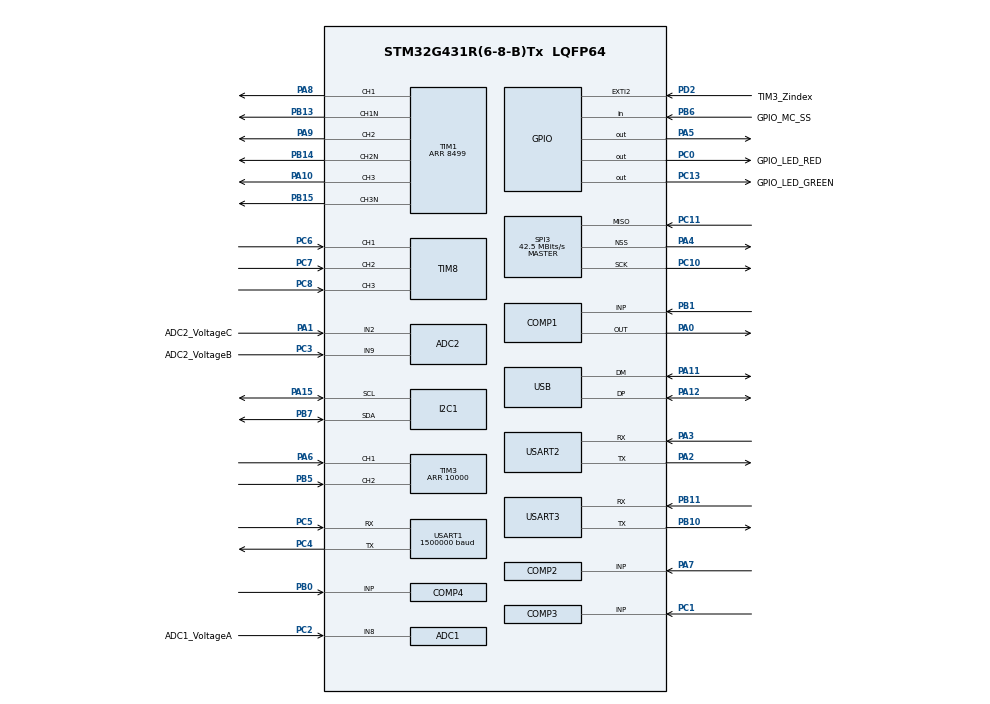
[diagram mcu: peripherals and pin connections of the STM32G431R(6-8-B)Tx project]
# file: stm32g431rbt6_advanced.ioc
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ADC1.Channel-0\#ChannelRegularConversion=ADC_CHANNEL_12
ADC1.Channel-2\#ChannelRegularConversion=ADC_CHANNEL_VREFINT
ADC1.DataAlign=ADC_DATAALIGN_LEFT
ADC1.EnableInjectedConversion=ENABLE
ADC1.ExternalTrigInjecConv=ADC_EXTERNALTRIGINJEC_T1_TRGO
ADC1.InjNumberOfConversion=3
ADC1.InjectedChannel-1\#ChannelInjectedConversion=ADC_CHANNEL_7
ADC1.InjectedChannel-3\#ChannelInjectedConversion=ADC_CHANNEL_8
ADC1.InjectedChannel-4\#ChannelInjectedConversion=ADC_CHANNEL_15
ADC1.InjectedOffsetNumber-1\#ChannelInjectedConversion=ADC_OFFSET_NONE
ADC1.InjectedOffsetNumber-3\#ChannelInjectedConversion=ADC_OFFSET_NONE
ADC1.InjectedOffsetNumber-4\#ChannelInjectedConversion=ADC_OFFSET_NONE
ADC1.InjectedRank-1\#ChannelInjectedConversion=1
ADC1.InjectedRank-3\#ChannelInjectedConversion=2
ADC1.InjectedRank-4\#ChannelInjectedConversion=3
ADC1.InjectedSamplingTime-1\#ChannelInjectedConversion=ADC_SAMPLETIME_2CYCLES_5
ADC1.InjectedSamplingTime-3\#ChannelInjectedConversion=ADC_SAMPLETIME_2CYCLES_5
ADC1.InjectedSamplingTime-4\#ChannelInjectedConversion=ADC_SAMPLETIME_2CYCLES_5
ADC1.NbrOfConversion=2
ADC1.NbrOfConversionFlag=1
ADC1.OffsetNumber-0\#ChannelRegularConversion=ADC_OFFSET_NONE
ADC1.OffsetNumber-2\#ChannelRegularConversion=ADC_OFFSET_NONE
ADC1.Rank-0\#ChannelRegularConversion=1
ADC1.Rank-2\#ChannelRegularConversion=2
ADC1.Rank2_Channel=ADC_CHANNEL_8
ADC1.Rank3_Channel=ADC_CHANNEL_15
ADC1.SamplingTime-0\#ChannelRegularConversion=ADC_SAMPLETIME_6CYCLES_5
ADC1.SamplingTime-2\#ChannelRegularConversion=ADC_SAMPLETIME_2CYCLES_5
ADC1.master=1
ADC2.DataAlign=ADC_DATAALIGN_LEFT
ADC2.EnableInjectedConversion=ENABLE
ADC2.EnableRegularConversion=DISABLE
ADC2.ExternalTrigInjecConv=ADC_EXTERNALTRIGINJEC_T1_TRGO
ADC2.InjNumberOfConversion=3
ADC2.InjectedChannel-1\#ChannelInjectedConversion=ADC_CHANNEL_4
ADC2.InjectedChannel-2\#ChannelInjectedConversion=ADC_CHANNEL_9
ADC2.InjectedChannel-3\#ChannelInjectedConversion=ADC_CHANNEL_2
ADC2.InjectedOffsetNumber-1\#ChannelInjectedConversion=ADC_OFFSET_NONE
ADC2.InjectedOffsetNumber-2\#ChannelInjectedConversion=ADC_OFFSET_NONE
ADC2.InjectedOffsetNumber-3\#ChannelInjectedConversion=ADC_OFFSET_NONE
ADC2.InjectedRank-1\#ChannelInjectedConversion=1
ADC2.InjectedRank-2\#ChannelInjectedConversion=2
ADC2.InjectedRank-3\#ChannelInjectedConversion=3
ADC2.InjectedSamplingTime-1\#ChannelInjectedConversion=ADC_SAMPLETIME_2CYCLES_5
ADC2.InjectedSamplingTime-2\#ChannelInjectedConversion=ADC_SAMPLETIME_2CYCLES_5
ADC2.InjectedSamplingTime-3\#ChannelInjectedConversion=ADC_SAMPLETIME_2CYCLES_5
ADC2.Rank1_Channel=ADC_CHANNEL_4
ADC2.Rank2_Channel=ADC_CHANNEL_9
ADC2.Rank3_Channel=ADC_CHANNEL_2
COMP1.Hysteresis=COMP_HYSTERESIS_70MV
COMP2.Hysteresis=COMP_HYSTERESIS_70MV
COMP3.Hysteresis=COMP_HYSTERESIS_70MV
COMP4.Hysteresis=COMP_HYSTERESIS_70MV
DAC3.DAC_Channel-DAC_OUT2_Int=DAC_CHANNEL_2
Dma.I2C1_RX.2.Direction=DMA_PERIPH_TO_MEMORY
Dma.I2C1_RX.2.EventEnable=DISABLE
Dma.I2C1_RX.2.Instance=DMA2_Channel2
Dma.I2C1_RX.2.MemDataAlignment=DMA_MDATAALIGN_BYTE
Dma.I2C1_RX.2.MemInc=DMA_MINC_ENABLE
Dma.I2C1_RX.2.Mode=DMA_CIRCULAR
Dma.I2C1_RX.2.PeriphDataAlignment=DMA_PDATAALIGN_BYTE
Dma.I2C1_RX.2.PeriphInc=DMA_PINC_DISABLE
Dma.I2C1_RX.2.Polarity=HAL_DMAMUX_REQ_GEN_RISING
Dma.I2C1_RX.2.Priority=DMA_PRIORITY_LOW
Dma.I2C1_RX.2.RequestNumber=1
Dma.I2C1_RX.2.SignalID=NONE
Dma.I2C1_RX.2.SyncEnable=DISABLE
Dma.I2C1_RX.2.SyncPolarity=HAL_DMAMUX_SYNC_NO_EVENT
Dma.I2C1_RX.2.SyncRequestNumber=1
Dma.I2C1_RX.2.SyncSignalID=NONE
Dma.Request0=USART1_RX
Dma.Request1=USART1_TX
Dma.Request2=I2C1_RX
Dma.Request3=SPI3_RX
Dma.SPI3_RX.3.Direction=DMA_PERIPH_TO_MEMORY
Dma.SPI3_RX.3.EventEnable=DISABLE
Dma.SPI3_RX.3.Instance=DMA2_Channel1
Dma.SPI3_RX.3.MemDataAlignment=DMA_MDATAALIGN_HALFWORD
Dma.SPI3_RX.3.MemInc=DMA_MINC_DISABLE
Dma.SPI3_RX.3.Mode=DMA_CIRCULAR
Dma.SPI3_RX.3.PeriphDataAlignment=DMA_PDATAALIGN_HALFWORD
Dma.SPI3_RX.3.PeriphInc=DMA_PINC_DISABLE
Dma.SPI3_RX.3.Polarity=HAL_DMAMUX_REQ_GEN_RISING
Dma.SPI3_RX.3.Priority=DMA_PRIORITY_LOW
Dma.SPI3_RX.3.RequestNumber=1
Dma.SPI3_RX.3.SignalID=NONE
Dma.SPI3_RX.3.SyncEnable=DISABLE
Dma.SPI3_RX.3.SyncPolarity=HAL_DMAMUX_SYNC_NO_EVENT
Dma.SPI3_RX.3.SyncRequestNumber=1
Dma.SPI3_RX.3.SyncSignalID=NONE
Dma.USART1_RX.0.Direction=DMA_PERIPH_TO_MEMORY
Dma.USART1_RX.0.EventEnable=DISABLE
Dma.USART1_RX.0.Instance=DMA1_Channel2
Dma.USART1_RX.0.MemDataAlignment=DMA_MDATAALIGN_BYTE
Dma.USART1_RX.0.MemInc=DMA_MINC_ENABLE
Dma.USART1_RX.0.Mode=DMA_CIRCULAR
Dma.USART1_RX.0.PeriphDataAlignment=DMA_PDATAALIGN_BYTE
Dma.USART1_RX.0.PeriphInc=DMA_PINC_DISABLE
Dma.USART1_RX.0.Polarity=HAL_DMAMUX_REQ_GEN_RISING
Dma.USART1_RX.0.Priority=DMA_PRIORITY_LOW
Dma.USART1_RX.0.RequestNumber=1
Dma.USART1_RX.0.SignalID=NONE
Dma.USART1_RX.0.SyncEnable=DISABLE
Dma.USART1_RX.0.SyncPolarity=HAL_DMAMUX_SYNC_NO_EVENT
Dma.USART1_RX.0.SyncRequestNumber=1
Dma.USART1_RX.0.SyncSignalID=NONE
Dma.USART1_TX.1.Direction=DMA_MEMORY_TO_PERIPH
Dma.USART1_TX.1.EventEnable=DISABLE
Dma.USART1_TX.1.Instance=DMA1_Channel1
Dma.USART1_TX.1.MemDataAlignment=DMA_MDATAALIGN_BYTE
Dma.USART1_TX.1.MemInc=DMA_MINC_ENABLE
Dma.USART1_TX.1.Mode=DMA_NORMAL
Dma.USART1_TX.1.PeriphDataAlignment=DMA_PDATAALIGN_BYTE
Dma.USART1_TX.1.PeriphInc=DMA_PINC_DISABLE
Dma.USART1_TX.1.Polarity=HAL_DMAMUX_REQ_GEN_RISING
Dma.USART1_TX.1.Priority=DMA_PRIORITY_LOW
Dma.USART1_TX.1.RequestNumber=1
Dma.USART1_TX.1.SignalID=NONE
Dma.USART1_TX.1.SyncEnable=DISABLE
Dma.USART1_TX.1.SyncPolarity=HAL_DMAMUX_SYNC_NO_EVENT
Dma.USART1_TX.1.SyncRequestNumber=1
Dma.USART1_TX.1.SyncSignalID=NONE
I2C1.Timing=0x30A0A7FB
Mcu.Family=STM32G4
Mcu.Name=STM32G431R(6-8-B)Tx
Mcu.Package=LQFP64
NVIC.ADC1_2_IRQn=true\:5\:0\:true\:false\:true\:true\:true\:true
NVIC.DMA1_Channel1_IRQn=true\:0\:0\:false\:false\:true\:false\:true\:true
NVIC.DMA1_Channel2_IRQn=true\:0\:0\:false\:false\:true\:false\:true\:true
NVIC.DMA2_Channel1_IRQn=true\:0\:0\:false\:false\:true\:false\:true\:true
NVIC.DMA2_Channel2_IRQn=true\:0\:0\:false\:false\:true\:false\:true\:true
NVIC.EXTI2_IRQn=true\:4\:0\:true\:false\:true\:true\:true\:true
NVIC.PriorityGroup=NVIC_PRIORITYGROUP_4
NVIC.USB_LP_IRQn=true\:0\:0\:false\:false\:true\:false\:true\:true
PA0.Mode=ExternalOutput
PA0.Signal=COMP1_OUT
PA1.GPIO_Label=ADC2_VoltageC
PA1.Mode=IN2-Single-Ended
PA1.Signal=ADC2_IN2
PA10.Signal=S_TIM1_CH3
PA11.Mode=Device
PA11.Signal=USB_DM
PA12.Mode=Device
PA12.Signal=USB_DP
PA13.Mode=Serial_Wire
PA13.Signal=SYS_JTMS-SWDIO
PA14.Mode=Serial_Wire
PA14.Signal=SYS_JTCK-SWCLK
PA15.GPIO_Pu=GPIO_PULLUP
PA15.Mode=I2C
PA15.Signal=I2C1_SCL
PA2.Mode=Asynchronous
PA2.Signal=USART2_TX
PA3.Mode=Asynchronous
PA3.Signal=USART2_RX
PA4.Mode=NSS_Signal_Hard_Output
PA4.Signal=SPI3_NSS
PA5.Signal=GPIO_Output
PA6.Signal=S_TIM3_CH1
PA7.Signal=SharedAnalog_PA7
PA8.Signal=S_TIM1_CH1
PA9.Signal=S_TIM1_CH2
PB0.Signal=SharedAnalog_PB0
PB1.Signal=SharedAnalog_PB1
PB10.Mode=Asynchronous
PB10.Signal=USART3_TX
PB11.Mode=Asynchronous
PB11.Signal=USART3_RX
PB13.Mode=PWM Generation1 CH1 CH1N
PB13.Signal=TIM1_CH1N
PB14.Mode=PWM Generation2 CH2 CH2N
PB14.Signal=TIM1_CH2N
PB15.Mode=PWM Generation3 CH3 CH3N
PB15.Signal=TIM1_CH3N
PB5.Signal=S_TIM3_CH2
PB6.GPIO_Label=GPIO_MC_SS
PB6.Signal=GPIO_Input
PB7.GPIO_Pu=GPIO_PULLUP
PB7.Mode=I2C
PB7.Signal=I2C1_SDA
PC0.GPIO_Label=GPIO_LED_RED
PC0.Signal=GPIO_Output
PC1.Signal=SharedAnalog_PC1
PC10.Mode=RX_Only_Simplex_Unidirect_Master
PC10.Signal=SPI3_SCK
PC11.Mode=RX_Only_Simplex_Unidirect_Master
PC11.Signal=SPI3_MISO
PC13.GPIO_Label=GPIO_LED_GREEN
PC13.Signal=GPIO_Output
PC14-OSC32_IN.Mode=LSE-External-Oscillator
PC14-OSC32_IN.Signal=RCC_OSC32_IN
PC15-OSC32_OUT.Mode=LSE-External-Oscillator
PC15-OSC32_OUT.Signal=RCC_OSC32_OUT
PC2.GPIO_Label=ADC1_VoltageA
PC2.Mode=IN8-Single-Ended
PC2.Signal=ADC1_IN8
PC3.GPIO_Label=ADC2_VoltageB
PC3.Mode=IN9-Single-Ended
PC3.Signal=ADC2_IN9
PC4.Mode=Asynchronous
PC4.Signal=USART1_TX
PC5.Mode=Asynchronous
PC5.Signal=USART1_RX
PC6.Signal=S_TIM8_CH1
PC7.Signal=S_TIM8_CH2
PC8.Signal=S_TIM8_CH3
PD2.GPIO_Label=TIM3_Zindex
PD2.GPIO_PuPd=GPIO_PULLDOWN
PD2.Signal=GPXTI2
PF0-OSC_IN.Mode=HSE-External-Oscillator
PF0-OSC_IN.Signal=RCC_OSC_IN
PF1-OSC_OUT.Mode=HSE-External-Oscillator
PF1-OSC_OUT.Signal=RCC_OSC_OUT
ProjectManager.HeapSize=0x200
ProjectManager.StackSize=0x400
ProjectManager.TargetToolchain=MDK-ARM V5.32
RCC.ADC12Freq_Value=170000000
RCC.AHBFreq_Value=170000000
RCC.APB1Freq_Value=170000000
RCC.APB1TimFreq_Value=170000000
RCC.APB2Freq_Value=170000000
RCC.APB2TimFreq_Value=170000000
RCC.CK48CLockSelection=RCC_USBCLKSOURCE_HSI48
RCC.CortexFreq_Value=170000000
RCC.EXTERNAL_CLOCK_VALUE=12288000
RCC.HCLKFreq_Value=170000000
RCC.HSE_VALUE=8000000
RCC.HSI48_VALUE=48000000
RCC.HSI_VALUE=16000000
RCC.PLLM=RCC_PLLM_DIV2
RCC.PLLN=85
RCC.PLLQ=RCC_PLLQ_DIV8
RCC.PLLSourceVirtual=RCC_PLLSOURCE_HSE
RCC.SYSCLKFreq_VALUE=170000000
RCC.SYSCLKSource=RCC_SYSCLKSOURCE_PLLCLK
RCC.USBFreq_Value=48000000
RCC.VCOOutputFreq_Value=340000000
SH.S_TIM1_CH1.0=TIM1_CH1,PWM Generation1 CH1 CH1N
SH.S_TIM1_CH2.0=TIM1_CH2,PWM Generation2 CH2 CH2N
SH.S_TIM1_CH3.0=TIM1_CH3,PWM Generation3 CH3 CH3N
SH.S_TIM3_CH1.0=TIM3_CH1,Encoder_Interface
SH.S_TIM3_CH2.0=TIM3_CH2,Encoder_Interface
SH.S_TIM8_CH1.0=TIM8_CH1,Xored_Inputs_Hall_Sensor_Interface
SH.S_TIM8_CH2.0=TIM8_CH2,Xored_Inputs_Hall_Sensor_Interface
SH.S_TIM8_CH3.0=TIM8_CH3,Xored_Inputs_Hall_Sensor_Interface
SH.SharedAnalog_PA7.0=COMP2_INP,INP
SH.SharedAnalog_PA7.1=ADC2_IN4,IN4-Single-Ended
SH.SharedAnalog_PB0.0=COMP4_INP,INP
SH.SharedAnalog_PB0.1=ADC1_IN15,IN15-Single-Ended
SH.SharedAnalog_PB1.0=COMP1_INP,INP
SH.SharedAnalog_PB1.1=ADC1_IN12,IN12-Single-Ended
SH.SharedAnalog_PC1.0=COMP3_INP,INP
SH.SharedAnalog_PC1.1=ADC1_IN7,IN7-Single-Ended
SPI3.BaudRatePrescaler=SPI_BAUDRATEPRESCALER_4
SPI3.CalculateBaudRate=42.5 MBits/s
SPI3.Direction=SPI_DIRECTION_2LINES_RXONLY
SPI3.Mode=SPI_MODE_MASTER
SPI3.VirtualNSS=VM_NSSHARD
SPI3.VirtualType=VM_MASTER
TIM1.Break2State=TIM_BREAK2_ENABLE
TIM1.BreakFilter=4
TIM1.BreakState=TIM_BREAK_ENABLE
TIM1.Channel-PWM\ Generation1\ CH1\ CH1N=TIM_CHANNEL_1
TIM1.Channel-PWM\ Generation2\ CH2\ CH2N=TIM_CHANNEL_2
TIM1.Channel-PWM\ Generation3\ CH3\ CH3N=TIM_CHANNEL_3
TIM1.CounterMode=TIM_COUNTERMODE_CENTERALIGNED1
TIM1.OCMode_PWM-PWM\ Generation1\ CH1\ CH1N=TIM_OCMODE_PWM2
TIM1.OCMode_PWM-PWM\ Generation2\ CH2\ CH2N=TIM_OCMODE_PWM2
TIM1.OCMode_PWM-PWM\ Generation3\ CH3\ CH3N=TIM_OCMODE_PWM2
TIM1.PeriodNoDither=8499
TIM1.RepetitionCounter=1
TIM1.SourceBRKCOMP2=TIM_BREAKINPUTSOURCE_ENABLE
TIM1.SourceBRKCOMP3=TIM_BREAKINPUTSOURCE_ENABLE
TIM1.SourceBRKCOMP4=TIM_BREAKINPUTSOURCE_ENABLE
TIM1.TIM_MasterOutputTrigger=TIM_TRGO_UPDATE
TIM3.EncoderMode=TIM_ENCODERMODE_TI12
TIM3.IC1Filter=3
TIM3.IC2Filter=3
TIM3.PeriodNoDither=10000
USART1.AutoBaudRateEnableParam=UART_ADVFEATURE_AUTOBAUDRATE_DISABLE
USART1.BaudRate=1500000
USART1.VirtualMode-Asynchronous=VM_ASYNC
USART2.VirtualMode-Asynchronous=VM_ASYNC
USART3.VirtualMode-Asynchronous=VM_ASYNC
USB.Sof_enable=DISABLE
USB_DEVICE.CLASS_NAME_FS=CDC
USB_DEVICE.VirtualMode=Cdc
USB_DEVICE.VirtualModeFS=Cdc_FS
VP_ADC1_Vref_Input.Mode=IN-Vrefint
VP_COMP1_VS_DAC1OUT1.Mode=INM_DAC1OUT1
VP_COMP2_VS_DAC3OUT2.Mode=INM_DAC3OUT2
VP_COMP3_VS_DAC3OUT1.Mode=INM_DAC3OUT1
VP_COMP4_VS_DAC3OUT2.Mode=INM_DAC3OUT2
VP_CORDIC_VS_CORDIC.Mode=CORDIC_Activate
VP_DAC1_VS_DACI1.Mode=DAC_OUT1_Int
VP_DAC3_VS_DACI1.Mode=DAC_OUT1_Int
VP_DAC3_VS_DACI2.Mode=DAC_OUT2_Int
VP_RNG_VS_RNG.Mode=RNG_Activate
VP_SYS_VS_DBSignals.Mode=DisableDeadBatterySignals
VP_SYS_V_VREFBUF.Mode=ExternalMode
VP_TIM16_VS_ClockSourceINT.Mode=Enable_Timer
VP_TIM1_VS_ClockSourceINT.Mode=Internal
VP_USB_DEVICE_VS_USB_DEVICE_CDC_FS.Mode=CDC_FS
board=custom

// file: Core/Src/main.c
/* USER CODE BEGIN Header */
/**
  ******************************************************************************
  * @file           : main.c
  * @brief          : Main program body
  ******************************************************************************
  * @attention
  *
  * Copyright (c) 2024 STMicroelectronics.
  * All rights reserved.
  *
  * This software is licensed under terms that can be found in the LICENSE file
  * in the root directory of this software component.
  * If no LICENSE file comes with this software, it is provided AS-IS.
  *
  ******************************************************************************
  */
/* USER CODE END Header */
#include "main.h"
#include "usb_device.h"

/* USER CODE BEGIN Includes */
#include "mcConfig.h"
#include "usbd_cdc_if.h"
/* USER CODE END Includes */

/* USER CODE BEGIN PM */
volatile uint16_t tempDat = 0u;
/* USER CODE END PM */

void SystemClock_Config(void);
static void MX_GPIO_Init(void);
static void MX_COMP1_Init(void);
static void MX_COMP2_Init(void);
static void MX_COMP3_Init(void);
static void MX_COMP4_Init(void);
static void MX_DAC1_Init(void);
static void MX_DAC3_Init(void);
static void MX_ADC1_Init(void);
static void MX_ADC2_Init(void);
static void MX_I2C1_Init(void);
static void MX_TIM1_Init(void);
static void MX_TIM8_Init(void);
static void MX_SPI3_Init(void);
static void MX_TIM3_Init(void);
static void MX_USART1_UART_Init(void);
static void MX_DMA_Init(void);
static void MX_USART3_UART_Init(void);
static void MX_USART2_UART_Init(void);
static void MX_CORDIC_Init(void);
static void MX_TIM16_Init(void);
static void MX_RNG_Init(void);

int main(void)
{

  /* MCU Configuration--------------------------------------------------------*/

  /* Reset of all peripherals, Initializes the Flash interface and the Systick. */
  HAL_Init();

  /* Configure the system clock */
  SystemClock_Config();

  /* Initialize all configured peripherals */
  MX_DMA_Init();
  MX_GPIO_Init();
  MX_COMP1_Init();
  MX_COMP2_Init();
  MX_COMP3_Init();
  MX_COMP4_Init();
  MX_DAC1_Init();
  MX_DAC3_Init();
  MX_ADC1_Init();
  MX_ADC2_Init();
  MX_I2C1_Init();
  MX_TIM1_Init();
  MX_TIM8_Init();
  MX_SPI3_Init();
  MX_TIM3_Init();
  MX_USART1_UART_Init();
  MX_USART3_UART_Init();
  MX_USART2_UART_Init();
  MX_CORDIC_Init();
  MX_TIM16_Init();
  MX_USB_Device_Init();
  MX_RNG_Init();
  /* USER CODE BEGIN 2 */
  /*=========================BOOT=================================*/
  uint32_t isBootFromMainFlash = READ_BIT(FLASH->SEC1R,FLASH_SEC1R_BOOT_LOCK);
  if(!isBootFromMainFlash){
    WRITE_REG(FLASH->KEYR,0x45670123);
    WRITE_REG(FLASH->KEYR,0xCDEF89AB);
    WRITE_REG(FLASH->OPTKEYR,0x08192A3B);
    WRITE_REG(FLASH->OPTKEYR,0x4C5D6E7F);
    while(READ_BIT(FLASH->SR,FLASH_SR_BSY));
    CLEAR_BIT(FLASH->CR,FLASH_CR_OPTLOCK);
    SET_BIT(FLASH->SEC1R,FLASH_SEC1R_BOOT_LOCK);
    SET_BIT(FLASH->CR,FLASH_CR_OPTSTRT);
    while(READ_BIT(FLASH->SR,FLASH_SR_BSY));
  }
  /*=========================Segger RTT=================================*/
  SEGGER_RTT_Init();

  /*===========================RNG===============================*/

  LL_RNG_Enable(RNG);

  /*===========================Cordic===============================*/

  LL_CORDIC_Config(CORDIC,LL_CORDIC_FUNCTION_SINE,LL_CORDIC_PRECISION_4CYCLES,LL_CORDIC_SCALE_0,LL_CORDIC_NBWRITE_1,LL_CORDIC_NBREAD_2,LL_CORDIC_INSIZE_32BITS,LL_CORDIC_OUTSIZE_32BITS);

  /*===========================CRC===============================*/

  /*===========================USB===============================*/

  USBD_Interface_fops_FS.Init();

  /*===========================OCP===============================*/

  LL_DAC_Enable(DAC3,LL_DAC_CHANNEL_1);
  LL_DAC_Enable(DAC3,LL_DAC_CHANNEL_2);

  LL_DAC_ConvertData12RightAligned(DAC3,LL_DAC_CHANNEL_1,4000);
  LL_DAC_ConvertData12RightAligned(DAC3,LL_DAC_CHANNEL_2,4000);

  LL_DAC_TrigSWConversion(DAC3,LL_DAC_CHANNEL_1);

  while(READ_BIT(DAC3->SWTRIGR,(LL_DAC_CHANNEL_1 & DAC_SWTR_CHX_MASK)));

  LL_DAC_TrigSWConversion(DAC3,LL_DAC_CHANNEL_2);

  while(READ_BIT(DAC3->SWTRIGR,(LL_DAC_CHANNEL_2 & DAC_SWTR_CHX_MASK)));

  LL_COMP_Enable(COMP2);
  LL_COMP_Enable(COMP3);
  LL_COMP_Enable(COMP4);
  /*===========================OVP===============================*/
  LL_DAC_Enable(DAC1,LL_DAC_CHANNEL_1);

  LL_DAC_ConvertData12RightAligned(DAC1,LL_DAC_CHANNEL_1,2500);

  LL_DAC_TrigSWConversion(DAC1,LL_DAC_CHANNEL_1);

  while(READ_BIT(DAC1->SWTRIGR,(LL_DAC_CHANNEL_1 & DAC_SWTR_CHX_MASK)));

  LL_COMP_Enable(COMP1);
  /*===========================SPI + DMA===============================*/
  // LL_SPI_EnableDMAReq_RX(SPI3);
  // LL_SPI_Enable(SPI3);

  // LL_DMA_ConfigAddresses(DMA2,LL_DMA_CHANNEL_1,(uint32_t)&SPI3->DR,(uint32_t)&pAbs->encoderOutput,LL_DMA_DIRECTION_PERIPH_TO_MEMORY);
  // LL_DMA_SetDataLength(DMA2,LL_DMA_CHANNEL_1,0xFFFF);
  // LL_DMA_EnableChannel(DMA2,LL_DMA_CHANNEL_1);
  /*===========================USART1 + TX +DMA===============================*/
  // LL_USART_EnableDMAReq_TX(USART1);
  // LL_DMA_ConfigAddresses(DMA1,LL_DMA_CHANNEL_1,(uint32_t)&frameSendForUSART,(uint32_t)&USART1->TDR,LL_DMA_DIRECTION_MEMORY_TO_PERIPH);
  // LL_DMA_SetDataLength(DMA1,LL_DMA_CHANNEL_1,sizeof(FrameSendForUSART));
  // LL_DMA_EnableChannel(DMA1,LL_DMA_CHANNEL_1);
  /*===========================USART1 + RX +DMA===============================*/
  // LL_USART_EnableDMAReq_RX(USART1);
  // LL_DMA_ConfigAddresses(DMA1,LL_DMA_CHANNEL_2,(uint32_t)&USART1->RDR,(uint32_t)&frameReceiveForUSART,LL_DMA_DIRECTION_PERIPH_TO_MEMORY);
  // LL_DMA_SetDataLength(DMA1,LL_DMA_CHANNEL_2,sizeof(FrameReceiveForUSART));
  // LL_DMA_EnableChannel(DMA1,LL_DMA_CHANNEL_2);
  /*===========================ADC===============================*/

  LL_ADC_StartCalibration(ADC1,LL_ADC_SINGLE_ENDED);
  while(LL_ADC_IsCalibrationOnGoing(ADC1)){

  }
  LL_ADC_StartCalibration(ADC2,LL_ADC_SINGLE_ENDED);
  while(LL_ADC_IsCalibrationOnGoing(ADC2)){

  }

  LL_ADC_INJ_StartConversion(ADC1);
  LL_ADC_EnableIT_JEOS(ADC1);
  LL_ADC_Enable(ADC1);

  LL_ADC_INJ_StartConversion(ADC2);
  LL_ADC_EnableIT_JEOS(ADC2);
  LL_ADC_Enable(ADC2);

  /*===========================TIM1 : Driver 3 phase===============================*/

  LL_TIM_OC_SetCompareCH1(TIM1,0);
  LL_TIM_OC_SetCompareCH2(TIM1,0);
  LL_TIM_OC_SetCompareCH3(TIM1,0);

  LL_TIM_EnableBRK(TIM1);

  LL_TIM_DisableAllOutputs(TIM1);
  LL_TIM_CC_DisableChannel(TIM1,LL_TIM_CHANNEL_CH1);
  LL_TIM_CC_DisableChannel(TIM1,LL_TIM_CHANNEL_CH1N);
  LL_TIM_CC_DisableChannel(TIM1,LL_TIM_CHANNEL_CH2);
  LL_TIM_CC_DisableChannel(TIM1,LL_TIM_CHANNEL_CH2N);
  LL_TIM_CC_DisableChannel(TIM1,LL_TIM_CHANNEL_CH3);
  LL_TIM_CC_DisableChannel(TIM1,LL_TIM_CHANNEL_CH3N);

  LL_TIM_EnableCounter(TIM1);
  /*===========================TIM8 : HALL Encoder===============================*/

  // LL_TIM_EnableCounter(TIM8);

  /*===========================TIM3 : ABZ Encoder===============================*/

	LL_TIM_EnableCounter(TIM3);

  /*===========================I2C + TEMP + DMA===============================*/

  LL_I2C_SetTransferRequest(I2C1,LL_I2C_REQUEST_READ);
  LL_I2C_SetSlaveAddr(I2C1,0x90);
  LL_I2C_SetTransferSize(I2C1,2);
  LL_I2C_EnableDMAReq_RX(I2C1);
  LL_I2C_Enable(I2C1);

  LL_DMA_ConfigAddresses(DMA2,LL_DMA_CHANNEL_2,(uint32_t)&I2C1->RXDR,(uint32_t)&tempDat,LL_DMA_DIRECTION_PERIPH_TO_MEMORY);
  LL_DMA_SetDataLength(DMA2,LL_DMA_CHANNEL_2,2);
  LL_DMA_EnableChannel(DMA2,LL_DMA_CHANNEL_2);

  /*===========================TIM 16 : work as a pulse clock===============================*/

  LL_TIM_EnableCounter(TIM16);

  /*===========================FOC start===============================*/

  LL_SYSTICK_EnableIT();
  NVIC_EnableIRQ(SysTick_IRQn);

  /* USER CODE END 2 */

  /* Infinite loop */
  while (1)
  {

  }
}

void SystemClock_Config(void)
{
  LL_FLASH_SetLatency(LL_FLASH_LATENCY_4);
  while(LL_FLASH_GetLatency() != LL_FLASH_LATENCY_4)
  {
  }
  LL_PWR_EnableRange1BoostMode();
  LL_RCC_HSE_Enable();
   /* Wait till HSE is ready */
  while(LL_RCC_HSE_IsReady() != 1)
  {
  }

  LL_RCC_HSI48_Enable();
   /* Wait till HSI48 is ready */
  while(LL_RCC_HSI48_IsReady() != 1)
  {
  }

  LL_RCC_PLL_ConfigDomain_SYS(LL_RCC_PLLSOURCE_HSE, LL_RCC_PLLM_DIV_2, 85, LL_RCC_PLLR_DIV_2);
  LL_RCC_PLL_EnableDomain_SYS();
  LL_RCC_PLL_Enable();
   /* Wait till PLL is ready */
  while(LL_RCC_PLL_IsReady() != 1)
  {
  }

  LL_RCC_SetSysClkSource(LL_RCC_SYS_CLKSOURCE_PLL);
  LL_RCC_SetAHBPrescaler(LL_RCC_SYSCLK_DIV_2);
   /* Wait till System clock is ready */
  while(LL_RCC_GetSysClkSource() != LL_RCC_SYS_CLKSOURCE_STATUS_PLL)
  {
  }

  /* Insure 1?s transition state at intermediate medium speed clock based on DWT */
  CoreDebug->DEMCR |= CoreDebug_DEMCR_TRCENA_Msk;
  DWT->CTRL |= DWT_CTRL_CYCCNTENA_Msk;
  DWT->CYCCNT = 0;
  while(DWT->CYCCNT < 100);
  /* Set AHB prescaler*/
  LL_RCC_SetAHBPrescaler(LL_RCC_SYSCLK_DIV_1);
  LL_RCC_SetAPB1Prescaler(LL_RCC_APB1_DIV_1);
  LL_RCC_SetAPB2Prescaler(LL_RCC_APB2_DIV_1);
  LL_SetSystemCoreClock(170000000);

   /* Update the time base */
  if (HAL_InitTick (TICK_INT_PRIORITY) != HAL_OK)
  {
    Error_Handler();
  }
}

static void MX_ADC1_Init(void)
{

  LL_ADC_InitTypeDef ADC_InitStruct = {0};
  LL_ADC_REG_InitTypeDef ADC_REG_InitStruct = {0};
  LL_ADC_CommonInitTypeDef ADC_CommonInitStruct = {0};
  LL_ADC_INJ_InitTypeDef ADC_INJ_InitStruct = {0};

  LL_GPIO_InitTypeDef GPIO_InitStruct = {0};

  LL_RCC_SetADCClockSource(LL_RCC_ADC12_CLKSOURCE_SYSCLK);

  /* Peripheral clock enable */
  LL_AHB2_GRP1_EnableClock(LL_AHB2_GRP1_PERIPH_ADC12);

  LL_AHB2_GRP1_EnableClock(LL_AHB2_GRP1_PERIPH_GPIOC);
  LL_AHB2_GRP1_EnableClock(LL_AHB2_GRP1_PERIPH_GPIOB);
  /**ADC1 GPIO Configuration
  PC1   ------> ADC1_IN7
  PC2   ------> ADC1_IN8
  PB0   ------> ADC1_IN15
  PB1   ------> ADC1_IN12
  */
  GPIO_InitStruct.Pin = LL_GPIO_PIN_1;
  GPIO_InitStruct.Mode = LL_GPIO_MODE_ANALOG;
  GPIO_InitStruct.Pull = LL_GPIO_PULL_NO;
  LL_GPIO_Init(GPIOC, &GPIO_InitStruct);

  GPIO_InitStruct.Pin = ADC1_VoltageA_Pin;
  GPIO_InitStruct.Mode = LL_GPIO_MODE_ANALOG;
  GPIO_InitStruct.Pull = LL_GPIO_PULL_NO;
  LL_GPIO_Init(ADC1_VoltageA_GPIO_Port, &GPIO_InitStruct);

  GPIO_InitStruct.Pin = LL_GPIO_PIN_0;
  GPIO_InitStruct.Mode = LL_GPIO_MODE_ANALOG;
  GPIO_InitStruct.Pull = LL_GPIO_PULL_NO;
  LL_GPIO_Init(GPIOB, &GPIO_InitStruct);

  GPIO_InitStruct.Pin = LL_GPIO_PIN_1;
  GPIO_InitStruct.Mode = LL_GPIO_MODE_ANALOG;
  GPIO_InitStruct.Pull = LL_GPIO_PULL_NO;
  LL_GPIO_Init(GPIOB, &GPIO_InitStruct);

  /* ADC1 interrupt Init */
  NVIC_SetPriority(ADC1_2_IRQn, NVIC_EncodePriority(NVIC_GetPriorityGrouping(),5, 0));
  NVIC_EnableIRQ(ADC1_2_IRQn);

  /** Common config
  */
  ADC_InitStruct.Resolution = LL_ADC_RESOLUTION_12B;
  ADC_InitStruct.DataAlignment = LL_ADC_DATA_ALIGN_LEFT;
  ADC_InitStruct.LowPowerMode = LL_ADC_LP_MODE_NONE;
  LL_ADC_Init(ADC1, &ADC_InitStruct);
  ADC_REG_InitStruct.TriggerSource = LL_ADC_REG_TRIG_SOFTWARE;
  ADC_REG_InitStruct.SequencerLength = LL_ADC_REG_SEQ_SCAN_ENABLE_2RANKS;
  ADC_REG_InitStruct.SequencerDiscont = LL_ADC_REG_SEQ_DISCONT_DISABLE;
  ADC_REG_InitStruct.ContinuousMode = LL_ADC_REG_CONV_SINGLE;
  ADC_REG_InitStruct.DMATransfer = LL_ADC_REG_DMA_TRANSFER_NONE;
  ADC_REG_InitStruct.Overrun = LL_ADC_REG_OVR_DATA_PRESERVED;
  LL_ADC_REG_Init(ADC1, &ADC_REG_InitStruct);
  LL_ADC_SetGainCompensation(ADC1, 0);
  LL_ADC_SetOverSamplingScope(ADC1, LL_ADC_OVS_DISABLE);
  ADC_CommonInitStruct.CommonClock = LL_ADC_CLOCK_SYNC_PCLK_DIV4;
  ADC_CommonInitStruct.Multimode = LL_ADC_MULTI_INDEPENDENT;
  LL_ADC_CommonInit(__LL_ADC_COMMON_INSTANCE(ADC1), &ADC_CommonInitStruct);
  ADC_INJ_InitStruct.TriggerSource = LL_ADC_INJ_TRIG_EXT_TIM1_TRGO;
  ADC_INJ_InitStruct.SequencerLength = LL_ADC_INJ_SEQ_SCAN_ENABLE_3RANKS;
  ADC_INJ_InitStruct.SequencerDiscont = LL_ADC_INJ_SEQ_DISCONT_DISABLE;
  ADC_INJ_InitStruct.TrigAuto = LL_ADC_INJ_TRIG_INDEPENDENT;
  LL_ADC_INJ_Init(ADC1, &ADC_INJ_InitStruct);
  LL_ADC_INJ_SetQueueMode(ADC1, LL_ADC_INJ_QUEUE_DISABLE);
  LL_ADC_INJ_SetTriggerEdge(ADC1, LL_ADC_INJ_TRIG_EXT_RISING);

  /* Disable ADC deep power down (enabled by default after reset state) */
  LL_ADC_DisableDeepPowerDown(ADC1);
  /* Enable ADC internal voltage regulator */
  LL_ADC_EnableInternalRegulator(ADC1);
  /* Delay for ADC internal voltage regulator stabilization. */
  /* Compute number of CPU cycles to wait for, from delay in us. */
  /* Note: Variable divided by 2 to compensate partially */
  /* CPU processing cycles (depends on compilation optimization). */
  /* Note: If system core clock frequency is below 200kHz, wait time */
  /* is only a few CPU processing cycles. */
  uint32_t wait_loop_index;
  wait_loop_index = ((LL_ADC_DELAY_INTERNAL_REGUL_STAB_US * (SystemCoreClock / (100000 * 2))) / 10);
  while(wait_loop_index != 0)
  {
    wait_loop_index--;
  }

  /** Configure Regular Channel
  */
  LL_ADC_REG_SetSequencerRanks(ADC1, LL_ADC_REG_RANK_1, LL_ADC_CHANNEL_12);
  LL_ADC_SetChannelSamplingTime(ADC1, LL_ADC_CHANNEL_12, LL_ADC_SAMPLINGTIME_6CYCLES_5);
  LL_ADC_SetChannelSingleDiff(ADC1, LL_ADC_CHANNEL_12, LL_ADC_SINGLE_ENDED);

  /** Configure Injected Channel
  */
  LL_ADC_INJ_SetSequencerRanks(ADC1, LL_ADC_INJ_RANK_1, LL_ADC_CHANNEL_7);
  LL_ADC_SetChannelSamplingTime(ADC1, LL_ADC_CHANNEL_7, LL_ADC_SAMPLINGTIME_2CYCLES_5);
  LL_ADC_SetChannelSingleDiff(ADC1, LL_ADC_CHANNEL_7, LL_ADC_SINGLE_ENDED);

  /** Configure Regular Channel
  */
  LL_ADC_REG_SetSequencerRanks(ADC1, LL_ADC_REG_RANK_2, LL_ADC_CHANNEL_VREFINT);
  LL_ADC_SetChannelSamplingTime(ADC1, LL_ADC_CHANNEL_VREFINT, LL_ADC_SAMPLINGTIME_2CYCLES_5);
  LL_ADC_SetChannelSingleDiff(ADC1, LL_ADC_CHANNEL_VREFINT, LL_ADC_SINGLE_ENDED);
  LL_ADC_SetCommonPathInternalCh(__LL_ADC_COMMON_INSTANCE(ADC1), LL_ADC_PATH_INTERNAL_VREFINT);

  /** Configure Injected Channel
  */
  LL_ADC_INJ_SetSequencerRanks(ADC1, LL_ADC_INJ_RANK_2, LL_ADC_CHANNEL_8);
  LL_ADC_SetChannelSamplingTime(ADC1, LL_ADC_CHANNEL_8, LL_ADC_SAMPLINGTIME_2CYCLES_5);
  LL_ADC_SetChannelSingleDiff(ADC1, LL_ADC_CHANNEL_8, LL_ADC_SINGLE_ENDED);

  /** Configure Injected Channel
  */
  LL_ADC_INJ_SetSequencerRanks(ADC1, LL_ADC_INJ_RANK_3, LL_ADC_CHANNEL_15);
  LL_ADC_SetChannelSamplingTime(ADC1, LL_ADC_CHANNEL_15, LL_ADC_SAMPLINGTIME_2CYCLES_5);
  LL_ADC_SetChannelSingleDiff(ADC1, LL_ADC_CHANNEL_15, LL_ADC_SINGLE_ENDED);

}

static void MX_ADC2_Init(void)
{

  LL_ADC_InitTypeDef ADC_InitStruct = {0};
  LL_ADC_REG_InitTypeDef ADC_REG_InitStruct = {0};
  LL_ADC_INJ_InitTypeDef ADC_INJ_InitStruct = {0};

  LL_GPIO_InitTypeDef GPIO_InitStruct = {0};

  LL_RCC_SetADCClockSource(LL_RCC_ADC12_CLKSOURCE_SYSCLK);

  /* Peripheral clock enable */
  LL_AHB2_GRP1_EnableClock(LL_AHB2_GRP1_PERIPH_ADC12);

  LL_AHB2_GRP1_EnableClock(LL_AHB2_GRP1_PERIPH_GPIOC);
  LL_AHB2_GRP1_EnableClock(LL_AHB2_GRP1_PERIPH_GPIOA);
  /**ADC2 GPIO Configuration
  PC3   ------> ADC2_IN9
  PA1   ------> ADC2_IN2
  PA7   ------> ADC2_IN4
  */
  GPIO_InitStruct.Pin = ADC2_VoltageB_Pin;
  GPIO_InitStruct.Mode = LL_GPIO_MODE_ANALOG;
  GPIO_InitStruct.Pull = LL_GPIO_PULL_NO;
  LL_GPIO_Init(ADC2_VoltageB_GPIO_Port, &GPIO_InitStruct);

  GPIO_InitStruct.Pin = ADC2_VoltageC_Pin;
  GPIO_InitStruct.Mode = LL_GPIO_MODE_ANALOG;
  GPIO_InitStruct.Pull = LL_GPIO_PULL_NO;
  LL_GPIO_Init(ADC2_VoltageC_GPIO_Port, &GPIO_InitStruct);

  GPIO_InitStruct.Pin = LL_GPIO_PIN_7;
  GPIO_InitStruct.Mode = LL_GPIO_MODE_ANALOG;
  GPIO_InitStruct.Pull = LL_GPIO_PULL_NO;
  LL_GPIO_Init(GPIOA, &GPIO_InitStruct);

  /* ADC2 interrupt Init */
  NVIC_SetPriority(ADC1_2_IRQn, NVIC_EncodePriority(NVIC_GetPriorityGrouping(),5, 0));
  NVIC_EnableIRQ(ADC1_2_IRQn);

  /** Common config
  */
  ADC_InitStruct.Resolution = LL_ADC_RESOLUTION_12B;
  ADC_InitStruct.DataAlignment = LL_ADC_DATA_ALIGN_LEFT;
  ADC_InitStruct.LowPowerMode = LL_ADC_LP_MODE_NONE;
  LL_ADC_Init(ADC2, &ADC_InitStruct);
  ADC_REG_InitStruct.SequencerLength = LL_ADC_REG_SEQ_SCAN_DISABLE;
  ADC_REG_InitStruct.SequencerDiscont = LL_ADC_REG_SEQ_DISCONT_DISABLE;
  ADC_REG_InitStruct.ContinuousMode = LL_ADC_REG_CONV_SINGLE;
  ADC_REG_InitStruct.DMATransfer = LL_ADC_REG_DMA_TRANSFER_NONE;
  ADC_REG_InitStruct.Overrun = LL_ADC_REG_OVR_DATA_PRESERVED;
  LL_ADC_REG_Init(ADC2, &ADC_REG_InitStruct);
  LL_ADC_SetGainCompensation(ADC2, 0);
  LL_ADC_SetOverSamplingScope(ADC2, LL_ADC_OVS_DISABLE);
  ADC_INJ_InitStruct.TriggerSource = LL_ADC_INJ_TRIG_EXT_TIM1_TRGO;
  ADC_INJ_InitStruct.SequencerLength = LL_ADC_INJ_SEQ_SCAN_ENABLE_3RANKS;
  ADC_INJ_InitStruct.SequencerDiscont = LL_ADC_INJ_SEQ_DISCONT_DISABLE;
  ADC_INJ_InitStruct.TrigAuto = LL_ADC_INJ_TRIG_INDEPENDENT;
  LL_ADC_INJ_Init(ADC2, &ADC_INJ_InitStruct);
  LL_ADC_INJ_SetQueueMode(ADC2, LL_ADC_INJ_QUEUE_DISABLE);
  LL_ADC_INJ_SetTriggerEdge(ADC2, LL_ADC_INJ_TRIG_EXT_RISING);

  /* Disable ADC deep power down (enabled by default after reset state) */
  LL_ADC_DisableDeepPowerDown(ADC2);
  /* Enable ADC internal voltage regulator */
  LL_ADC_EnableInternalRegulator(ADC2);
  /* Delay for ADC internal voltage regulator stabilization. */
  /* Compute number of CPU cycles to wait for, from delay in us. */
  /* Note: Variable divided by 2 to compensate partially */
  /* CPU processing cycles (depends on compilation optimization). */
  /* Note: If system core clock frequency is below 200kHz, wait time */
  /* is only a few CPU processing cycles. */
  uint32_t wait_loop_index;
  wait_loop_index = ((LL_ADC_DELAY_INTERNAL_REGUL_STAB_US * (SystemCoreClock / (100000 * 2))) / 10);
  while(wait_loop_index != 0)
  {
    wait_loop_index--;
  }

  /** Configure Injected Channel
  */
  LL_ADC_INJ_SetSequencerRanks(ADC2, LL_ADC_INJ_RANK_1, LL_ADC_CHANNEL_4);
  LL_ADC_SetChannelSamplingTime(ADC2, LL_ADC_CHANNEL_4, LL_ADC_SAMPLINGTIME_2CYCLES_5);
  LL_ADC_SetChannelSingleDiff(ADC2, LL_ADC_CHANNEL_4, LL_ADC_SINGLE_ENDED);

  /** Configure Injected Channel
  */
  LL_ADC_INJ_SetSequencerRanks(ADC2, LL_ADC_INJ_RANK_2, LL_ADC_CHANNEL_9);
  LL_ADC_SetChannelSamplingTime(ADC2, LL_ADC_CHANNEL_9, LL_ADC_SAMPLINGTIME_2CYCLES_5);
  LL_ADC_SetChannelSingleDiff(ADC2, LL_ADC_CHANNEL_9, LL_ADC_SINGLE_ENDED);

  /** Configure Injected Channel
  */
  LL_ADC_INJ_SetSequencerRanks(ADC2, LL_ADC_INJ_RANK_3, LL_ADC_CHANNEL_2);
  LL_ADC_SetChannelSamplingTime(ADC2, LL_ADC_CHANNEL_2, LL_ADC_SAMPLINGTIME_2CYCLES_5);
  LL_ADC_SetChannelSingleDiff(ADC2, LL_ADC_CHANNEL_2, LL_ADC_SINGLE_ENDED);

}

static void MX_COMP1_Init(void)
{

  LL_COMP_InitTypeDef COMP_InitStruct = {0};

  LL_GPIO_InitTypeDef GPIO_InitStruct = {0};

  LL_AHB2_GRP1_EnableClock(LL_AHB2_GRP1_PERIPH_GPIOA);
  LL_AHB2_GRP1_EnableClock(LL_AHB2_GRP1_PERIPH_GPIOB);
  /**COMP1 GPIO Configuration
  PA0   ------> COMP1_OUT
  PB1   ------> COMP1_INP
  */
  GPIO_InitStruct.Pin = LL_GPIO_PIN_0;
  GPIO_InitStruct.Mode = LL_GPIO_MODE_ALTERNATE;
  GPIO_InitStruct.Speed = LL_GPIO_SPEED_FREQ_LOW;
  GPIO_InitStruct.OutputType = LL_GPIO_OUTPUT_PUSHPULL;
  GPIO_InitStruct.Pull = LL_GPIO_PULL_NO;
  GPIO_InitStruct.Alternate = LL_GPIO_AF_8;
  LL_GPIO_Init(GPIOA, &GPIO_InitStruct);

  GPIO_InitStruct.Pin = LL_GPIO_PIN_1;
  GPIO_InitStruct.Mode = LL_GPIO_MODE_ANALOG;
  GPIO_InitStruct.Pull = LL_GPIO_PULL_NO;
  LL_GPIO_Init(GPIOB, &GPIO_InitStruct);

  COMP_InitStruct.InputPlus = LL_COMP_INPUT_PLUS_IO2;
  COMP_InitStruct.InputMinus = LL_COMP_INPUT_MINUS_DAC1_CH1;
  COMP_InitStruct.InputHysteresis = LL_COMP_HYSTERESIS_70MV;
  COMP_InitStruct.OutputPolarity = LL_COMP_OUTPUTPOL_NONINVERTED;
  COMP_InitStruct.OutputBlankingSource = LL_COMP_BLANKINGSRC_NONE;
  LL_COMP_Init(COMP1, &COMP_InitStruct);

  /* Wait loop initialization and execution */
  /* Note: Variable divided by 2 to compensate partially CPU processing cycles */
  __IO uint32_t wait_loop_index = 0;
  wait_loop_index = (LL_COMP_DELAY_VOLTAGE_SCALER_STAB_US * (SystemCoreClock / (1000000 * 2)));
  while(wait_loop_index != 0)
  {
    wait_loop_index--;
  }
  LL_EXTI_DisableEvent_0_31(LL_EXTI_LINE_21);
  LL_EXTI_DisableIT_0_31(LL_EXTI_LINE_21);

}

static void MX_COMP2_Init(void)
{

  LL_COMP_InitTypeDef COMP_InitStruct = {0};

  LL_GPIO_InitTypeDef GPIO_InitStruct = {0};

  LL_AHB2_GRP1_EnableClock(LL_AHB2_GRP1_PERIPH_GPIOA);
  /**COMP2 GPIO Configuration
  PA7   ------> COMP2_INP
  */
  GPIO_InitStruct.Pin = LL_GPIO_PIN_7;
  GPIO_InitStruct.Mode = LL_GPIO_MODE_ANALOG;
  GPIO_InitStruct.Pull = LL_GPIO_PULL_NO;
  LL_GPIO_Init(GPIOA, &GPIO_InitStruct);

  COMP_InitStruct.InputPlus = LL_COMP_INPUT_PLUS_IO1;
  COMP_InitStruct.InputMinus = LL_COMP_INPUT_MINUS_DAC3_CH2;
  COMP_InitStruct.InputHysteresis = LL_COMP_HYSTERESIS_70MV;
  COMP_InitStruct.OutputPolarity = LL_COMP_OUTPUTPOL_NONINVERTED;
  COMP_InitStruct.OutputBlankingSource = LL_COMP_BLANKINGSRC_NONE;
  LL_COMP_Init(COMP2, &COMP_InitStruct);

  /* Wait loop initialization and execution */
  /* Note: Variable divided by 2 to compensate partially CPU processing cycles */
  __IO uint32_t wait_loop_index = 0;
  wait_loop_index = (LL_COMP_DELAY_VOLTAGE_SCALER_STAB_US * (SystemCoreClock / (1000000 * 2)));
  while(wait_loop_index != 0)
  {
    wait_loop_index--;
  }
  LL_EXTI_DisableEvent_0_31(LL_EXTI_LINE_22);
  LL_EXTI_DisableIT_0_31(LL_EXTI_LINE_22);

}

static void MX_COMP3_Init(void)
{

  LL_COMP_InitTypeDef COMP_InitStruct = {0};

  LL_GPIO_InitTypeDef GPIO_InitStruct = {0};

  LL_AHB2_GRP1_EnableClock(LL_AHB2_GRP1_PERIPH_GPIOC);
  /**COMP3 GPIO Configuration
  PC1   ------> COMP3_INP
  */
  GPIO_InitStruct.Pin = LL_GPIO_PIN_1;
  GPIO_InitStruct.Mode = LL_GPIO_MODE_ANALOG;
  GPIO_InitStruct.Pull = LL_GPIO_PULL_NO;
  LL_GPIO_Init(GPIOC, &GPIO_InitStruct);

  COMP_InitStruct.InputPlus = LL_COMP_INPUT_PLUS_IO2;
  COMP_InitStruct.InputMinus = LL_COMP_INPUT_MINUS_DAC3_CH1;
  COMP_InitStruct.InputHysteresis = LL_COMP_HYSTERESIS_70MV;
  COMP_InitStruct.OutputPolarity = LL_COMP_OUTPUTPOL_NONINVERTED;
  COMP_InitStruct.OutputBlankingSource = LL_COMP_BLANKINGSRC_NONE;
  LL_COMP_Init(COMP3, &COMP_InitStruct);

  /* Wait loop initialization and execution */
  /* Note: Variable divided by 2 to compensate partially CPU processing cycles */
  __IO uint32_t wait_loop_index = 0;
  wait_loop_index = (LL_COMP_DELAY_VOLTAGE_SCALER_STAB_US * (SystemCoreClock / (1000000 * 2)));
  while(wait_loop_index != 0)
  {
    wait_loop_index--;
  }
  LL_EXTI_DisableEvent_0_31(LL_EXTI_LINE_29);
  LL_EXTI_DisableIT_0_31(LL_EXTI_LINE_29);

}

static void MX_COMP4_Init(void)
{

  LL_COMP_InitTypeDef COMP_InitStruct = {0};

  LL_GPIO_InitTypeDef GPIO_InitStruct = {0};

  LL_AHB2_GRP1_EnableClock(LL_AHB2_GRP1_PERIPH_GPIOB);
  /**COMP4 GPIO Configuration
  PB0   ------> COMP4_INP
  */
  GPIO_InitStruct.Pin = LL_GPIO_PIN_0;
  GPIO_InitStruct.Mode = LL_GPIO_MODE_ANALOG;
  GPIO_InitStruct.Pull = LL_GPIO_PULL_NO;
  LL_GPIO_Init(GPIOB, &GPIO_InitStruct);

  COMP_InitStruct.InputPlus = LL_COMP_INPUT_PLUS_IO1;
  COMP_InitStruct.InputMinus = LL_COMP_INPUT_MINUS_DAC3_CH2;
  COMP_InitStruct.InputHysteresis = LL_COMP_HYSTERESIS_70MV;
  COMP_InitStruct.OutputPolarity = LL_COMP_OUTPUTPOL_NONINVERTED;
  COMP_InitStruct.OutputBlankingSource = LL_COMP_BLANKINGSRC_NONE;
  LL_COMP_Init(COMP4, &COMP_InitStruct);

  /* Wait loop initialization and execution */
  /* Note: Variable divided by 2 to compensate partially CPU processing cycles */
  __IO uint32_t wait_loop_index = 0;
  wait_loop_index = (LL_COMP_DELAY_VOLTAGE_SCALER_STAB_US * (SystemCoreClock / (1000000 * 2)));
  while(wait_loop_index != 0)
  {
    wait_loop_index--;
  }
  LL_EXTI_DisableEvent_0_31(LL_EXTI_LINE_30);
  LL_EXTI_DisableIT_0_31(LL_EXTI_LINE_30);

}

static void MX_CORDIC_Init(void)
{

  /* Peripheral clock enable */
  LL_AHB1_GRP1_EnableClock(LL_AHB1_GRP1_PERIPH_CORDIC);

  /* nothing else to be configured */

}

static void MX_DAC1_Init(void)
{

  LL_DAC_InitTypeDef DAC_InitStruct = {0};

  /* Peripheral clock enable */
  LL_AHB2_GRP1_EnableClock(LL_AHB2_GRP1_PERIPH_DAC1);

  /** DAC channel OUT1 config
  */
  LL_DAC_SetSignedFormat(DAC1, LL_DAC_CHANNEL_1, LL_DAC_SIGNED_FORMAT_DISABLE);
  DAC_InitStruct.TriggerSource = LL_DAC_TRIG_SOFTWARE;
  DAC_InitStruct.TriggerSource2 = LL_DAC_TRIG_SOFTWARE;
  DAC_InitStruct.WaveAutoGeneration = LL_DAC_WAVE_AUTO_GENERATION_NONE;
  DAC_InitStruct.OutputBuffer = LL_DAC_OUTPUT_BUFFER_DISABLE;
  DAC_InitStruct.OutputConnection = LL_DAC_OUTPUT_CONNECT_INTERNAL;
  DAC_InitStruct.OutputMode = LL_DAC_OUTPUT_MODE_NORMAL;
  LL_DAC_Init(DAC1, LL_DAC_CHANNEL_1, &DAC_InitStruct);
  LL_DAC_DisableTrigger(DAC1, LL_DAC_CHANNEL_1);
  LL_DAC_DisableDMADoubleDataMode(DAC1, LL_DAC_CHANNEL_1);

}

static void MX_DAC3_Init(void)
{

  LL_DAC_InitTypeDef DAC_InitStruct = {0};

  /* Peripheral clock enable */
  LL_AHB2_GRP1_EnableClock(LL_AHB2_GRP1_PERIPH_DAC3);

  /** DAC channel OUT1 config
  */
  LL_DAC_SetSignedFormat(DAC3, LL_DAC_CHANNEL_1, LL_DAC_SIGNED_FORMAT_DISABLE);
  DAC_InitStruct.TriggerSource = LL_DAC_TRIG_SOFTWARE;
  DAC_InitStruct.TriggerSource2 = LL_DAC_TRIG_SOFTWARE;
  DAC_InitStruct.WaveAutoGeneration = LL_DAC_WAVE_AUTO_GENERATION_NONE;
  DAC_InitStruct.OutputBuffer = LL_DAC_OUTPUT_BUFFER_DISABLE;
  DAC_InitStruct.OutputConnection = LL_DAC_OUTPUT_CONNECT_INTERNAL;
  DAC_InitStruct.OutputMode = LL_DAC_OUTPUT_MODE_NORMAL;
  LL_DAC_Init(DAC3, LL_DAC_CHANNEL_1, &DAC_InitStruct);
  LL_DAC_DisableTrigger(DAC3, LL_DAC_CHANNEL_1);
  LL_DAC_DisableDMADoubleDataMode(DAC3, LL_DAC_CHANNEL_1);

  /** DAC channel OUT2 config
  */
  LL_DAC_SetSignedFormat(DAC3, LL_DAC_CHANNEL_2, LL_DAC_SIGNED_FORMAT_DISABLE);
  LL_DAC_Init(DAC3, LL_DAC_CHANNEL_2, &DAC_InitStruct);
  LL_DAC_DisableTrigger(DAC3, LL_DAC_CHANNEL_2);
  LL_DAC_DisableDMADoubleDataMode(DAC3, LL_DAC_CHANNEL_2);

}

static void MX_I2C1_Init(void)
{

  LL_I2C_InitTypeDef I2C_InitStruct = {0};

  LL_GPIO_InitTypeDef GPIO_InitStruct = {0};

  LL_RCC_SetI2CClockSource(LL_RCC_I2C1_CLKSOURCE_PCLK1);

  LL_AHB2_GRP1_EnableClock(LL_AHB2_GRP1_PERIPH_GPIOA);
  LL_AHB2_GRP1_EnableClock(LL_AHB2_GRP1_PERIPH_GPIOB);
  /**I2C1 GPIO Configuration
  PA15   ------> I2C1_SCL
  PB7   ------> I2C1_SDA
  */
  GPIO_InitStruct.Pin = LL_GPIO_PIN_15;
  GPIO_InitStruct.Mode = LL_GPIO_MODE_ALTERNATE;
  GPIO_InitStruct.Speed = LL_GPIO_SPEED_FREQ_LOW;
  GPIO_InitStruct.OutputType = LL_GPIO_OUTPUT_OPENDRAIN;
  GPIO_InitStruct.Pull = LL_GPIO_PULL_UP;
  GPIO_InitStruct.Alternate = LL_GPIO_AF_4;
  LL_GPIO_Init(GPIOA, &GPIO_InitStruct);

  GPIO_InitStruct.Pin = LL_GPIO_PIN_7;
  GPIO_InitStruct.Mode = LL_GPIO_MODE_ALTERNATE;
  GPIO_InitStruct.Speed = LL_GPIO_SPEED_FREQ_LOW;
  GPIO_InitStruct.OutputType = LL_GPIO_OUTPUT_OPENDRAIN;
  GPIO_InitStruct.Pull = LL_GPIO_PULL_UP;
  GPIO_InitStruct.Alternate = LL_GPIO_AF_4;
  LL_GPIO_Init(GPIOB, &GPIO_InitStruct);

  /* Peripheral clock enable */
  LL_APB1_GRP1_EnableClock(LL_APB1_GRP1_PERIPH_I2C1);

  /* I2C1 DMA Init */

  /* I2C1_RX Init */
  LL_DMA_SetPeriphRequest(DMA2, LL_DMA_CHANNEL_2, LL_DMAMUX_REQ_I2C1_RX);

  LL_DMA_SetDataTransferDirection(DMA2, LL_DMA_CHANNEL_2, LL_DMA_DIRECTION_PERIPH_TO_MEMORY);

  LL_DMA_SetChannelPriorityLevel(DMA2, LL_DMA_CHANNEL_2, LL_DMA_PRIORITY_LOW);

  LL_DMA_SetMode(DMA2, LL_DMA_CHANNEL_2, LL_DMA_MODE_CIRCULAR);

  LL_DMA_SetPeriphIncMode(DMA2, LL_DMA_CHANNEL_2, LL_DMA_PERIPH_NOINCREMENT);

  LL_DMA_SetMemoryIncMode(DMA2, LL_DMA_CHANNEL_2, LL_DMA_MEMORY_INCREMENT);

  LL_DMA_SetPeriphSize(DMA2, LL_DMA_CHANNEL_2, LL_DMA_PDATAALIGN_BYTE);

  LL_DMA_SetMemorySize(DMA2, LL_DMA_CHANNEL_2, LL_DMA_MDATAALIGN_BYTE);

  /** I2C Initialization
  */
  I2C_InitStruct.PeripheralMode = LL_I2C_MODE_I2C;
  I2C_InitStruct.Timing = 0x30A0A7FB;
  I2C_InitStruct.AnalogFilter = LL_I2C_ANALOGFILTER_ENABLE;
  I2C_InitStruct.DigitalFilter = 0;
  I2C_InitStruct.OwnAddress1 = 0;
  I2C_InitStruct.TypeAcknowledge = LL_I2C_ACK;
  I2C_InitStruct.OwnAddrSize = LL_I2C_OWNADDRESS1_7BIT;
  LL_I2C_Init(I2C1, &I2C_InitStruct);
  LL_I2C_EnableAutoEndMode(I2C1);
  LL_I2C_SetOwnAddress2(I2C1, 0, LL_I2C_OWNADDRESS2_NOMASK);
  LL_I2C_DisableOwnAddress2(I2C1);
  LL_I2C_DisableGeneralCall(I2C1);
  LL_I2C_EnableClockStretching(I2C1);

}

static void MX_RNG_Init(void)
{

  LL_RCC_SetRNGClockSource(LL_RCC_RNG_CLKSOURCE_HSI48);

  /* Peripheral clock enable */
  LL_AHB2_GRP1_EnableClock(LL_AHB2_GRP1_PERIPH_RNG);

  LL_RNG_Enable(RNG);

}

static void MX_SPI3_Init(void)
{

  LL_SPI_InitTypeDef SPI_InitStruct = {0};

  LL_GPIO_InitTypeDef GPIO_InitStruct = {0};

  /* Peripheral clock enable */
  LL_APB1_GRP1_EnableClock(LL_APB1_GRP1_PERIPH_SPI3);

  LL_AHB2_GRP1_EnableClock(LL_AHB2_GRP1_PERIPH_GPIOA);
  LL_AHB2_GRP1_EnableClock(LL_AHB2_GRP1_PERIPH_GPIOC);
  /**SPI3 GPIO Configuration
  PA4   ------> SPI3_NSS
  PC10   ------> SPI3_SCK
  PC11   ------> SPI3_MISO
  */
  GPIO_InitStruct.Pin = LL_GPIO_PIN_4;
  GPIO_InitStruct.Mode = LL_GPIO_MODE_ALTERNATE;
  GPIO_InitStruct.Speed = LL_GPIO_SPEED_FREQ_LOW;
  GPIO_InitStruct.OutputType = LL_GPIO_OUTPUT_PUSHPULL;
  GPIO_InitStruct.Pull = LL_GPIO_PULL_NO;
  GPIO_InitStruct.Alternate = LL_GPIO_AF_6;
  LL_GPIO_Init(GPIOA, &GPIO_InitStruct);

  GPIO_InitStruct.Pin = LL_GPIO_PIN_10;
  GPIO_InitStruct.Mode = LL_GPIO_MODE_ALTERNATE;
  GPIO_InitStruct.Speed = LL_GPIO_SPEED_FREQ_LOW;
  GPIO_InitStruct.OutputType = LL_GPIO_OUTPUT_PUSHPULL;
  GPIO_InitStruct.Pull = LL_GPIO_PULL_NO;
  GPIO_InitStruct.Alternate = LL_GPIO_AF_6;
  LL_GPIO_Init(GPIOC, &GPIO_InitStruct);

  GPIO_InitStruct.Pin = LL_GPIO_PIN_11;
  GPIO_InitStruct.Mode = LL_GPIO_MODE_ALTERNATE;
  GPIO_InitStruct.Speed = LL_GPIO_SPEED_FREQ_LOW;
  GPIO_InitStruct.OutputType = LL_GPIO_OUTPUT_PUSHPULL;
  GPIO_InitStruct.Pull = LL_GPIO_PULL_NO;
  GPIO_InitStruct.Alternate = LL_GPIO_AF_6;
  LL_GPIO_Init(GPIOC, &GPIO_InitStruct);

  /* SPI3 DMA Init */

  /* SPI3_RX Init */
  LL_DMA_SetPeriphRequest(DMA2, LL_DMA_CHANNEL_1, LL_DMAMUX_REQ_SPI3_RX);

  LL_DMA_SetDataTransferDirection(DMA2, LL_DMA_CHANNEL_1, LL_DMA_DIRECTION_PERIPH_TO_MEMORY);

  LL_DMA_SetChannelPriorityLevel(DMA2, LL_DMA_CHANNEL_1, LL_DMA_PRIORITY_LOW);

  LL_DMA_SetMode(DMA2, LL_DMA_CHANNEL_1, LL_DMA_MODE_CIRCULAR);

  LL_DMA_SetPeriphIncMode(DMA2, LL_DMA_CHANNEL_1, LL_DMA_PERIPH_NOINCREMENT);

  LL_DMA_SetMemoryIncMode(DMA2, LL_DMA_CHANNEL_1, LL_DMA_MEMORY_NOINCREMENT);

  LL_DMA_SetPeriphSize(DMA2, LL_DMA_CHANNEL_1, LL_DMA_PDATAALIGN_HALFWORD);

  LL_DMA_SetMemorySize(DMA2, LL_DMA_CHANNEL_1, LL_DMA_MDATAALIGN_HALFWORD);

  /* SPI3 parameter configuration*/
  SPI_InitStruct.TransferDirection = LL_SPI_SIMPLEX_RX;
  SPI_InitStruct.Mode = LL_SPI_MODE_MASTER;
  SPI_InitStruct.DataWidth = LL_SPI_DATAWIDTH_4BIT;
  SPI_InitStruct.ClockPolarity = LL_SPI_POLARITY_LOW;
  SPI_InitStruct.ClockPhase = LL_SPI_PHASE_1EDGE;
  SPI_InitStruct.NSS = LL_SPI_NSS_HARD_OUTPUT;
  SPI_InitStruct.BaudRate = LL_SPI_BAUDRATEPRESCALER_DIV4;
  SPI_InitStruct.BitOrder = LL_SPI_MSB_FIRST;
  SPI_InitStruct.CRCCalculation = LL_SPI_CRCCALCULATION_DISABLE;
  SPI_InitStruct.CRCPoly = 7;
  LL_SPI_Init(SPI3, &SPI_InitStruct);
  LL_SPI_SetStandard(SPI3, LL_SPI_PROTOCOL_MOTOROLA);
  LL_SPI_EnableNSSPulseMgt(SPI3);

}

static void MX_TIM1_Init(void)
{

  LL_TIM_InitTypeDef TIM_InitStruct = {0};
  LL_TIM_OC_InitTypeDef TIM_OC_InitStruct = {0};
  LL_TIM_BDTR_InitTypeDef TIM_BDTRInitStruct = {0};

  LL_GPIO_InitTypeDef GPIO_InitStruct = {0};

  /* Peripheral clock enable */
  LL_APB2_GRP1_EnableClock(LL_APB2_GRP1_PERIPH_TIM1);

  TIM_InitStruct.Prescaler = 0;
  TIM_InitStruct.CounterMode = LL_TIM_COUNTERMODE_CENTER_UP;
  TIM_InitStruct.Autoreload = 8499;
  TIM_InitStruct.ClockDivision = LL_TIM_CLOCKDIVISION_DIV1;
  TIM_InitStruct.RepetitionCounter = 1;
  LL_TIM_Init(TIM1, &TIM_InitStruct);
  LL_TIM_DisableARRPreload(TIM1);
  LL_TIM_SetClockSource(TIM1, LL_TIM_CLOCKSOURCE_INTERNAL);
  LL_TIM_OC_EnablePreload(TIM1, LL_TIM_CHANNEL_CH1);
  TIM_OC_InitStruct.OCMode = LL_TIM_OCMODE_PWM2;
  TIM_OC_InitStruct.OCState = LL_TIM_OCSTATE_DISABLE;
  TIM_OC_InitStruct.OCNState = LL_TIM_OCSTATE_DISABLE;
  TIM_OC_InitStruct.CompareValue = 0;
  TIM_OC_InitStruct.OCPolarity = LL_TIM_OCPOLARITY_HIGH;
  TIM_OC_InitStruct.OCNPolarity = LL_TIM_OCPOLARITY_HIGH;
  TIM_OC_InitStruct.OCIdleState = LL_TIM_OCIDLESTATE_LOW;
  TIM_OC_InitStruct.OCNIdleState = LL_TIM_OCIDLESTATE_LOW;
  LL_TIM_OC_Init(TIM1, LL_TIM_CHANNEL_CH1, &TIM_OC_InitStruct);
  LL_TIM_OC_DisableFast(TIM1, LL_TIM_CHANNEL_CH1);
  LL_TIM_OC_EnablePreload(TIM1, LL_TIM_CHANNEL_CH2);
  LL_TIM_OC_Init(TIM1, LL_TIM_CHANNEL_CH2, &TIM_OC_InitStruct);
  LL_TIM_OC_DisableFast(TIM1, LL_TIM_CHANNEL_CH2);
  LL_TIM_OC_EnablePreload(TIM1, LL_TIM_CHANNEL_CH3);
  LL_TIM_OC_Init(TIM1, LL_TIM_CHANNEL_CH3, &TIM_OC_InitStruct);
  LL_TIM_OC_DisableFast(TIM1, LL_TIM_CHANNEL_CH3);
  LL_TIM_SetTriggerOutput(TIM1, LL_TIM_TRGO_UPDATE);
  LL_TIM_SetTriggerOutput2(TIM1, LL_TIM_TRGO2_RESET);
  LL_TIM_DisableMasterSlaveMode(TIM1);
  LL_TIM_SetBreakInputSourcePolarity(TIM1, LL_TIM_BREAK_INPUT_BKIN, LL_TIM_BKIN_SOURCE_BKCOMP2, LL_TIM_BKIN_POLARITY_HIGH);
  LL_TIM_EnableBreakInputSource(TIM1, LL_TIM_BREAK_INPUT_BKIN, LL_TIM_BKIN_SOURCE_BKCOMP2);
  LL_TIM_SetBreakInputSourcePolarity(TIM1, LL_TIM_BREAK_INPUT_BKIN, LL_TIM_BKIN_SOURCE_BKCOMP3, LL_TIM_BKIN_POLARITY_HIGH);
  LL_TIM_EnableBreakInputSource(TIM1, LL_TIM_BREAK_INPUT_BKIN, LL_TIM_BKIN_SOURCE_BKCOMP3);
  LL_TIM_SetBreakInputSourcePolarity(TIM1, LL_TIM_BREAK_INPUT_BKIN, LL_TIM_BKIN_SOURCE_BKCOMP4, LL_TIM_BKIN_POLARITY_HIGH);
  LL_TIM_EnableBreakInputSource(TIM1, LL_TIM_BREAK_INPUT_BKIN, LL_TIM_BKIN_SOURCE_BKCOMP4);
  TIM_BDTRInitStruct.OSSRState = LL_TIM_OSSR_DISABLE;
  TIM_BDTRInitStruct.OSSIState = LL_TIM_OSSI_DISABLE;
  TIM_BDTRInitStruct.LockLevel = LL_TIM_LOCKLEVEL_OFF;
  TIM_BDTRInitStruct.DeadTime = 0;
  TIM_BDTRInitStruct.BreakState = LL_TIM_BREAK_ENABLE;
  TIM_BDTRInitStruct.BreakPolarity = LL_TIM_BREAK_POLARITY_HIGH;
  TIM_BDTRInitStruct.BreakFilter = LL_TIM_BREAK_FILTER_FDIV2_N6;
  TIM_BDTRInitStruct.BreakAFMode = LL_TIM_BREAK_AFMODE_INPUT;
  TIM_BDTRInitStruct.Break2State = LL_TIM_BREAK2_ENABLE;
  TIM_BDTRInitStruct.Break2Polarity = LL_TIM_BREAK2_POLARITY_HIGH;
  TIM_BDTRInitStruct.Break2Filter = LL_TIM_BREAK2_FILTER_FDIV1;
  TIM_BDTRInitStruct.Break2AFMode = LL_TIM_BREAK_AFMODE_INPUT;
  TIM_BDTRInitStruct.AutomaticOutput = LL_TIM_AUTOMATICOUTPUT_DISABLE;
  LL_TIM_BDTR_Init(TIM1, &TIM_BDTRInitStruct);
  LL_AHB2_GRP1_EnableClock(LL_AHB2_GRP1_PERIPH_GPIOB);
  LL_AHB2_GRP1_EnableClock(LL_AHB2_GRP1_PERIPH_GPIOA);
  /**TIM1 GPIO Configuration
  PB13   ------> TIM1_CH1N
  PB14   ------> TIM1_CH2N
  PB15   ------> TIM1_CH3N
  PA8   ------> TIM1_CH1
  PA9   ------> TIM1_CH2
  PA10   ------> TIM1_CH3
  */
  GPIO_InitStruct.Pin = LL_GPIO_PIN_13;
  GPIO_InitStruct.Mode = LL_GPIO_MODE_ALTERNATE;
  GPIO_InitStruct.Speed = LL_GPIO_SPEED_FREQ_LOW;
  GPIO_InitStruct.OutputType = LL_GPIO_OUTPUT_PUSHPULL;
  GPIO_InitStruct.Pull = LL_GPIO_PULL_NO;
  GPIO_InitStruct.Alternate = LL_GPIO_AF_6;
  LL_GPIO_Init(GPIOB, &GPIO_InitStruct);

  GPIO_InitStruct.Pin = LL_GPIO_PIN_14;
  GPIO_InitStruct.Mode = LL_GPIO_MODE_ALTERNATE;
  GPIO_InitStruct.Speed = LL_GPIO_SPEED_FREQ_LOW;
  GPIO_InitStruct.OutputType = LL_GPIO_OUTPUT_PUSHPULL;
  GPIO_InitStruct.Pull = LL_GPIO_PULL_NO;
  GPIO_InitStruct.Alternate = LL_GPIO_AF_6;
  LL_GPIO_Init(GPIOB, &GPIO_InitStruct);

  GPIO_InitStruct.Pin = LL_GPIO_PIN_15;
  GPIO_InitStruct.Mode = LL_GPIO_MODE_ALTERNATE;
  GPIO_InitStruct.Speed = LL_GPIO_SPEED_FREQ_LOW;
  GPIO_InitStruct.OutputType = LL_GPIO_OUTPUT_PUSHPULL;
  GPIO_InitStruct.Pull = LL_GPIO_PULL_NO;
  GPIO_InitStruct.Alternate = LL_GPIO_AF_4;
  LL_GPIO_Init(GPIOB, &GPIO_InitStruct);

  GPIO_InitStruct.Pin = LL_GPIO_PIN_8;
  GPIO_InitStruct.Mode = LL_GPIO_MODE_ALTERNATE;
  GPIO_InitStruct.Speed = LL_GPIO_SPEED_FREQ_LOW;
  GPIO_InitStruct.OutputType = LL_GPIO_OUTPUT_PUSHPULL;
  GPIO_InitStruct.Pull = LL_GPIO_PULL_NO;
  GPIO_InitStruct.Alternate = LL_GPIO_AF_6;
  LL_GPIO_Init(GPIOA, &GPIO_InitStruct);

  GPIO_InitStruct.Pin = LL_GPIO_PIN_9;
  GPIO_InitStruct.Mode = LL_GPIO_MODE_ALTERNATE;
  GPIO_InitStruct.Speed = LL_GPIO_SPEED_FREQ_LOW;
  GPIO_InitStruct.OutputType = LL_GPIO_OUTPUT_PUSHPULL;
  GPIO_InitStruct.Pull = LL_GPIO_PULL_NO;
  GPIO_InitStruct.Alternate = LL_GPIO_AF_6;
  LL_GPIO_Init(GPIOA, &GPIO_InitStruct);

  GPIO_InitStruct.Pin = LL_GPIO_PIN_10;
  GPIO_InitStruct.Mode = LL_GPIO_MODE_ALTERNATE;
  GPIO_InitStruct.Speed = LL_GPIO_SPEED_FREQ_LOW;
  GPIO_InitStruct.OutputType = LL_GPIO_OUTPUT_PUSHPULL;
  GPIO_InitStruct.Pull = LL_GPIO_PULL_NO;
  GPIO_InitStruct.Alternate = LL_GPIO_AF_6;
  LL_GPIO_Init(GPIOA, &GPIO_InitStruct);

}

static void MX_TIM3_Init(void)
{

  LL_TIM_InitTypeDef TIM_InitStruct = {0};

  LL_GPIO_InitTypeDef GPIO_InitStruct = {0};

  /* Peripheral clock enable */
  LL_APB1_GRP1_EnableClock(LL_APB1_GRP1_PERIPH_TIM3);

  LL_AHB2_GRP1_EnableClock(LL_AHB2_GRP1_PERIPH_GPIOA);
  LL_AHB2_GRP1_EnableClock(LL_AHB2_GRP1_PERIPH_GPIOB);
  /**TIM3 GPIO Configuration
  PA6   ------> TIM3_CH1
  PB5   ------> TIM3_CH2
  */
  GPIO_InitStruct.Pin = LL_GPIO_PIN_6;
  GPIO_InitStruct.Mode = LL_GPIO_MODE_ALTERNATE;
  GPIO_InitStruct.Speed = LL_GPIO_SPEED_FREQ_LOW;
  GPIO_InitStruct.OutputType = LL_GPIO_OUTPUT_PUSHPULL;
  GPIO_InitStruct.Pull = LL_GPIO_PULL_NO;
  GPIO_InitStruct.Alternate = LL_GPIO_AF_2;
  LL_GPIO_Init(GPIOA, &GPIO_InitStruct);

  GPIO_InitStruct.Pin = LL_GPIO_PIN_5;
  GPIO_InitStruct.Mode = LL_GPIO_MODE_ALTERNATE;
  GPIO_InitStruct.Speed = LL_GPIO_SPEED_FREQ_LOW;
  GPIO_InitStruct.OutputType = LL_GPIO_OUTPUT_PUSHPULL;
  GPIO_InitStruct.Pull = LL_GPIO_PULL_NO;
  GPIO_InitStruct.Alternate = LL_GPIO_AF_2;
  LL_GPIO_Init(GPIOB, &GPIO_InitStruct);

  TIM_InitStruct.Prescaler = 0;
  TIM_InitStruct.CounterMode = LL_TIM_COUNTERMODE_UP;
  TIM_InitStruct.Autoreload = 10000;
  TIM_InitStruct.ClockDivision = LL_TIM_CLOCKDIVISION_DIV1;
  LL_TIM_Init(TIM3, &TIM_InitStruct);
  LL_TIM_DisableARRPreload(TIM3);
  LL_TIM_SetEncoderMode(TIM3, LL_TIM_ENCODERMODE_X4_TI12);
  LL_TIM_IC_SetActiveInput(TIM3, LL_TIM_CHANNEL_CH1, LL_TIM_ACTIVEINPUT_DIRECTTI);
  LL_TIM_IC_SetPrescaler(TIM3, LL_TIM_CHANNEL_CH1, LL_TIM_ICPSC_DIV1);
  LL_TIM_IC_SetFilter(TIM3, LL_TIM_CHANNEL_CH1, LL_TIM_IC_FILTER_FDIV1_N8);
  LL_TIM_IC_SetPolarity(TIM3, LL_TIM_CHANNEL_CH1, LL_TIM_IC_POLARITY_RISING);
  LL_TIM_IC_SetActiveInput(TIM3, LL_TIM_CHANNEL_CH2, LL_TIM_ACTIVEINPUT_DIRECTTI);
  LL_TIM_IC_SetPrescaler(TIM3, LL_TIM_CHANNEL_CH2, LL_TIM_ICPSC_DIV1);
  LL_TIM_IC_SetFilter(TIM3, LL_TIM_CHANNEL_CH2, LL_TIM_IC_FILTER_FDIV1_N8);
  LL_TIM_IC_SetPolarity(TIM3, LL_TIM_CHANNEL_CH2, LL_TIM_IC_POLARITY_RISING);
  LL_TIM_SetTriggerOutput(TIM3, LL_TIM_TRGO_RESET);
  LL_TIM_DisableMasterSlaveMode(TIM3);

}

static void MX_TIM8_Init(void)
{

  LL_TIM_InitTypeDef TIM_InitStruct = {0};
  LL_TIM_OC_InitTypeDef TIM_OC_InitStruct = {0};

  LL_GPIO_InitTypeDef GPIO_InitStruct = {0};

  /* Peripheral clock enable */
  LL_APB2_GRP1_EnableClock(LL_APB2_GRP1_PERIPH_TIM8);

  LL_AHB2_GRP1_EnableClock(LL_AHB2_GRP1_PERIPH_GPIOC);
  /**TIM8 GPIO Configuration
  PC6   ------> TIM8_CH1
  PC7   ------> TIM8_CH2
  PC8   ------> TIM8_CH3
  */
  GPIO_InitStruct.Pin = LL_GPIO_PIN_6;
  GPIO_InitStruct.Mode = LL_GPIO_MODE_ALTERNATE;
  GPIO_InitStruct.Speed = LL_GPIO_SPEED_FREQ_LOW;
  GPIO_InitStruct.OutputType = LL_GPIO_OUTPUT_PUSHPULL;
  GPIO_InitStruct.Pull = LL_GPIO_PULL_NO;
  GPIO_InitStruct.Alternate = LL_GPIO_AF_4;
  LL_GPIO_Init(GPIOC, &GPIO_InitStruct);

  GPIO_InitStruct.Pin = LL_GPIO_PIN_7;
  GPIO_InitStruct.Mode = LL_GPIO_MODE_ALTERNATE;
  GPIO_InitStruct.Speed = LL_GPIO_SPEED_FREQ_LOW;
  GPIO_InitStruct.OutputType = LL_GPIO_OUTPUT_PUSHPULL;
  GPIO_InitStruct.Pull = LL_GPIO_PULL_NO;
  GPIO_InitStruct.Alternate = LL_GPIO_AF_4;
  LL_GPIO_Init(GPIOC, &GPIO_InitStruct);

  GPIO_InitStruct.Pin = LL_GPIO_PIN_8;
  GPIO_InitStruct.Mode = LL_GPIO_MODE_ALTERNATE;
  GPIO_InitStruct.Speed = LL_GPIO_SPEED_FREQ_LOW;
  GPIO_InitStruct.OutputType = LL_GPIO_OUTPUT_PUSHPULL;
  GPIO_InitStruct.Pull = LL_GPIO_PULL_NO;
  GPIO_InitStruct.Alternate = LL_GPIO_AF_4;
  LL_GPIO_Init(GPIOC, &GPIO_InitStruct);

  TIM_InitStruct.Prescaler = 0;
  TIM_InitStruct.CounterMode = LL_TIM_COUNTERMODE_UP;
  TIM_InitStruct.Autoreload = 65535;
  TIM_InitStruct.ClockDivision = LL_TIM_CLOCKDIVISION_DIV1;
  TIM_InitStruct.RepetitionCounter = 0;
  LL_TIM_Init(TIM8, &TIM_InitStruct);
  LL_TIM_DisableARRPreload(TIM8);
  LL_TIM_CC_DisableChannel(TIM8, LL_TIM_CHANNEL_CH1 | LL_TIM_CHANNEL_CH2);
  LL_TIM_IC_SetActiveInput(TIM8, LL_TIM_CHANNEL_CH1, LL_TIM_ACTIVEINPUT_TRC);
  LL_TIM_IC_SetPrescaler(TIM8, LL_TIM_CHANNEL_CH1, LL_TIM_ICPSC_DIV1);
  LL_TIM_IC_SetFilter(TIM8, LL_TIM_CHANNEL_CH1, LL_TIM_IC_FILTER_FDIV1);
  LL_TIM_IC_SetPolarity(TIM8, LL_TIM_CHANNEL_CH1, LL_TIM_IC_POLARITY_RISING);
  LL_TIM_IC_EnableXORCombination(TIM8);
  LL_TIM_SetTriggerInput(TIM8, LL_TIM_TS_TI1F_ED);
  LL_TIM_SetSlaveMode(TIM8, LL_TIM_SLAVEMODE_RESET);
  TIM_OC_InitStruct.OCMode = LL_TIM_OCMODE_PWM2;
  TIM_OC_InitStruct.OCState = LL_TIM_OCSTATE_DISABLE;
  TIM_OC_InitStruct.OCNState = LL_TIM_OCSTATE_DISABLE;
  TIM_OC_InitStruct.CompareValue = 0;
  TIM_OC_InitStruct.OCPolarity = LL_TIM_OCPOLARITY_HIGH;
  TIM_OC_InitStruct.OCNPolarity = LL_TIM_OCPOLARITY_HIGH;
  TIM_OC_InitStruct.OCIdleState = LL_TIM_OCIDLESTATE_LOW;
  TIM_OC_InitStruct.OCNIdleState = LL_TIM_OCIDLESTATE_LOW;

  LL_TIM_OC_Init(TIM8, LL_TIM_CHANNEL_CH2, &TIM_OC_InitStruct);
  LL_TIM_OC_DisableFast(TIM8, LL_TIM_CHANNEL_CH2);
  LL_TIM_SetTriggerOutput(TIM8, LL_TIM_TRGO_OC2REF);
  LL_TIM_SetTriggerOutput2(TIM8, LL_TIM_TRGO2_RESET);
  LL_TIM_DisableMasterSlaveMode(TIM8);

}

static void MX_TIM16_Init(void)
{

  LL_TIM_InitTypeDef TIM_InitStruct = {0};

  /* Peripheral clock enable */
  LL_APB2_GRP1_EnableClock(LL_APB2_GRP1_PERIPH_TIM16);

  TIM_InitStruct.Prescaler = 0;
  TIM_InitStruct.CounterMode = LL_TIM_COUNTERMODE_UP;
  TIM_InitStruct.Autoreload = 65535;
  TIM_InitStruct.ClockDivision = LL_TIM_CLOCKDIVISION_DIV1;
  TIM_InitStruct.RepetitionCounter = 0;
  LL_TIM_Init(TIM16, &TIM_InitStruct);
  LL_TIM_DisableARRPreload(TIM16);

}

static void MX_USART1_UART_Init(void)
{

  LL_USART_InitTypeDef USART_InitStruct = {0};

  LL_GPIO_InitTypeDef GPIO_InitStruct = {0};

  LL_RCC_SetUSARTClockSource(LL_RCC_USART1_CLKSOURCE_PCLK2);

  /* Peripheral clock enable */
  LL_APB2_GRP1_EnableClock(LL_APB2_GRP1_PERIPH_USART1);

  LL_AHB2_GRP1_EnableClock(LL_AHB2_GRP1_PERIPH_GPIOC);
  /**USART1 GPIO Configuration
  PC4   ------> USART1_TX
  PC5   ------> USART1_RX
  */
  GPIO_InitStruct.Pin = LL_GPIO_PIN_4;
  GPIO_InitStruct.Mode = LL_GPIO_MODE_ALTERNATE;
  GPIO_InitStruct.Speed = LL_GPIO_SPEED_FREQ_LOW;
  GPIO_InitStruct.OutputType = LL_GPIO_OUTPUT_PUSHPULL;
  GPIO_InitStruct.Pull = LL_GPIO_PULL_NO;
  GPIO_InitStruct.Alternate = LL_GPIO_AF_7;
  LL_GPIO_Init(GPIOC, &GPIO_InitStruct);

  GPIO_InitStruct.Pin = LL_GPIO_PIN_5;
  GPIO_InitStruct.Mode = LL_GPIO_MODE_ALTERNATE;
  GPIO_InitStruct.Speed = LL_GPIO_SPEED_FREQ_LOW;
  GPIO_InitStruct.OutputType = LL_GPIO_OUTPUT_PUSHPULL;
  GPIO_InitStruct.Pull = LL_GPIO_PULL_NO;
  GPIO_InitStruct.Alternate = LL_GPIO_AF_7;
  LL_GPIO_Init(GPIOC, &GPIO_InitStruct);

  /* USART1 DMA Init */

  /* USART1_RX Init */
  LL_DMA_SetPeriphRequest(DMA1, LL_DMA_CHANNEL_2, LL_DMAMUX_REQ_USART1_RX);

  LL_DMA_SetDataTransferDirection(DMA1, LL_DMA_CHANNEL_2, LL_DMA_DIRECTION_PERIPH_TO_MEMORY);

  LL_DMA_SetChannelPriorityLevel(DMA1, LL_DMA_CHANNEL_2, LL_DMA_PRIORITY_LOW);

  LL_DMA_SetMode(DMA1, LL_DMA_CHANNEL_2, LL_DMA_MODE_CIRCULAR);

  LL_DMA_SetPeriphIncMode(DMA1, LL_DMA_CHANNEL_2, LL_DMA_PERIPH_NOINCREMENT);

  LL_DMA_SetMemoryIncMode(DMA1, LL_DMA_CHANNEL_2, LL_DMA_MEMORY_INCREMENT);

  LL_DMA_SetPeriphSize(DMA1, LL_DMA_CHANNEL_2, LL_DMA_PDATAALIGN_BYTE);

  LL_DMA_SetMemorySize(DMA1, LL_DMA_CHANNEL_2, LL_DMA_MDATAALIGN_BYTE);

  /* USART1_TX Init */
  LL_DMA_SetPeriphRequest(DMA1, LL_DMA_CHANNEL_1, LL_DMAMUX_REQ_USART1_TX);

  LL_DMA_SetDataTransferDirection(DMA1, LL_DMA_CHANNEL_1, LL_DMA_DIRECTION_MEMORY_TO_PERIPH);

  LL_DMA_SetChannelPriorityLevel(DMA1, LL_DMA_CHANNEL_1, LL_DMA_PRIORITY_LOW);

  LL_DMA_SetMode(DMA1, LL_DMA_CHANNEL_1, LL_DMA_MODE_NORMAL);

  LL_DMA_SetPeriphIncMode(DMA1, LL_DMA_CHANNEL_1, LL_DMA_PERIPH_NOINCREMENT);

  LL_DMA_SetMemoryIncMode(DMA1, LL_DMA_CHANNEL_1, LL_DMA_MEMORY_INCREMENT);

  LL_DMA_SetPeriphSize(DMA1, LL_DMA_CHANNEL_1, LL_DMA_PDATAALIGN_BYTE);

  LL_DMA_SetMemorySize(DMA1, LL_DMA_CHANNEL_1, LL_DMA_MDATAALIGN_BYTE);

  USART_InitStruct.PrescalerValue = LL_USART_PRESCALER_DIV1;
  USART_InitStruct.BaudRate = 1500000;
  USART_InitStruct.DataWidth = LL_USART_DATAWIDTH_8B;
  USART_InitStruct.StopBits = LL_USART_STOPBITS_1;
  USART_InitStruct.Parity = LL_USART_PARITY_NONE;
  USART_InitStruct.TransferDirection = LL_USART_DIRECTION_TX_RX;
  USART_InitStruct.HardwareFlowControl = LL_USART_HWCONTROL_NONE;
  USART_InitStruct.OverSampling = LL_USART_OVERSAMPLING_16;
  LL_USART_Init(USART1, &USART_InitStruct);
  LL_USART_SetTXFIFOThreshold(USART1, LL_USART_FIFOTHRESHOLD_1_8);
  LL_USART_SetRXFIFOThreshold(USART1, LL_USART_FIFOTHRESHOLD_1_8);
  LL_USART_DisableFIFO(USART1);
  LL_USART_ConfigAsyncMode(USART1);

  LL_USART_Enable(USART1);

  /* Polling USART1 initialisation */
  while((!(LL_USART_IsActiveFlag_TEACK(USART1))) || (!(LL_USART_IsActiveFlag_REACK(USART1))))
  {
  }

}

static void MX_USART2_UART_Init(void)
{

  LL_USART_InitTypeDef USART_InitStruct = {0};

  LL_GPIO_InitTypeDef GPIO_InitStruct = {0};

  LL_RCC_SetUSARTClockSource(LL_RCC_USART2_CLKSOURCE_PCLK1);

  /* Peripheral clock enable */
  LL_APB1_GRP1_EnableClock(LL_APB1_GRP1_PERIPH_USART2);

  LL_AHB2_GRP1_EnableClock(LL_AHB2_GRP1_PERIPH_GPIOA);
  /**USART2 GPIO Configuration
  PA2   ------> USART2_TX
  PA3   ------> USART2_RX
  */
  GPIO_InitStruct.Pin = LL_GPIO_PIN_2;
  GPIO_InitStruct.Mode = LL_GPIO_MODE_ALTERNATE;
  GPIO_InitStruct.Speed = LL_GPIO_SPEED_FREQ_LOW;
  GPIO_InitStruct.OutputType = LL_GPIO_OUTPUT_PUSHPULL;
  GPIO_InitStruct.Pull = LL_GPIO_PULL_NO;
  GPIO_InitStruct.Alternate = LL_GPIO_AF_7;
  LL_GPIO_Init(GPIOA, &GPIO_InitStruct);

  GPIO_InitStruct.Pin = LL_GPIO_PIN_3;
  GPIO_InitStruct.Mode = LL_GPIO_MODE_ALTERNATE;
  GPIO_InitStruct.Speed = LL_GPIO_SPEED_FREQ_LOW;
  GPIO_InitStruct.OutputType = LL_GPIO_OUTPUT_PUSHPULL;
  GPIO_InitStruct.Pull = LL_GPIO_PULL_NO;
  GPIO_InitStruct.Alternate = LL_GPIO_AF_7;
  LL_GPIO_Init(GPIOA, &GPIO_InitStruct);

  USART_InitStruct.PrescalerValue = LL_USART_PRESCALER_DIV1;
  USART_InitStruct.BaudRate = 115200;
  USART_InitStruct.DataWidth = LL_USART_DATAWIDTH_8B;
  USART_InitStruct.StopBits = LL_USART_STOPBITS_1;
  USART_InitStruct.Parity = LL_USART_PARITY_NONE;
  USART_InitStruct.TransferDirection = LL_USART_DIRECTION_TX_RX;
  USART_InitStruct.HardwareFlowControl = LL_USART_HWCONTROL_NONE;
  USART_InitStruct.OverSampling = LL_USART_OVERSAMPLING_16;
  LL_USART_Init(USART2, &USART_InitStruct);
  LL_USART_SetTXFIFOThreshold(USART2, LL_USART_FIFOTHRESHOLD_1_8);
  LL_USART_SetRXFIFOThreshold(USART2, LL_USART_FIFOTHRESHOLD_1_8);
  LL_USART_DisableFIFO(USART2);
  LL_USART_ConfigAsyncMode(USART2);

  LL_USART_Enable(USART2);

  /* Polling USART2 initialisation */
  while((!(LL_USART_IsActiveFlag_TEACK(USART2))) || (!(LL_USART_IsActiveFlag_REACK(USART2))))
  {
  }

}

static void MX_USART3_UART_Init(void)
{

  LL_USART_InitTypeDef USART_InitStruct = {0};

  LL_GPIO_InitTypeDef GPIO_InitStruct = {0};

  LL_RCC_SetUSARTClockSource(LL_RCC_USART3_CLKSOURCE_PCLK1);

  /* Peripheral clock enable */
  LL_APB1_GRP1_EnableClock(LL_APB1_GRP1_PERIPH_USART3);

  LL_AHB2_GRP1_EnableClock(LL_AHB2_GRP1_PERIPH_GPIOB);
  /**USART3 GPIO Configuration
  PB10   ------> USART3_TX
  PB11   ------> USART3_RX
  */
  GPIO_InitStruct.Pin = LL_GPIO_PIN_10;
  GPIO_InitStruct.Mode = LL_GPIO_MODE_ALTERNATE;
  GPIO_InitStruct.Speed = LL_GPIO_SPEED_FREQ_LOW;
  GPIO_InitStruct.OutputType = LL_GPIO_OUTPUT_PUSHPULL;
  GPIO_InitStruct.Pull = LL_GPIO_PULL_NO;
  GPIO_InitStruct.Alternate = LL_GPIO_AF_7;
  LL_GPIO_Init(GPIOB, &GPIO_InitStruct);

  GPIO_InitStruct.Pin = LL_GPIO_PIN_11;
  GPIO_InitStruct.Mode = LL_GPIO_MODE_ALTERNATE;
  GPIO_InitStruct.Speed = LL_GPIO_SPEED_FREQ_LOW;
  GPIO_InitStruct.OutputType = LL_GPIO_OUTPUT_PUSHPULL;
  GPIO_InitStruct.Pull = LL_GPIO_PULL_NO;
  GPIO_InitStruct.Alternate = LL_GPIO_AF_7;
  LL_GPIO_Init(GPIOB, &GPIO_InitStruct);

  USART_InitStruct.PrescalerValue = LL_USART_PRESCALER_DIV1;
  USART_InitStruct.BaudRate = 115200;
  USART_InitStruct.DataWidth = LL_USART_DATAWIDTH_8B;
  USART_InitStruct.StopBits = LL_USART_STOPBITS_1;
  USART_InitStruct.Parity = LL_USART_PARITY_NONE;
  USART_InitStruct.TransferDirection = LL_USART_DIRECTION_TX_RX;
  USART_InitStruct.HardwareFlowControl = LL_USART_HWCONTROL_NONE;
  USART_InitStruct.OverSampling = LL_USART_OVERSAMPLING_16;
  LL_USART_Init(USART3, &USART_InitStruct);
  LL_USART_SetTXFIFOThreshold(USART3, LL_USART_FIFOTHRESHOLD_1_8);
  LL_USART_SetRXFIFOThreshold(USART3, LL_USART_FIFOTHRESHOLD_1_8);
  LL_USART_DisableFIFO(USART3);
  LL_USART_ConfigAsyncMode(USART3);

  LL_USART_Enable(USART3);

  /* Polling USART3 initialisation */
  while((!(LL_USART_IsActiveFlag_TEACK(USART3))) || (!(LL_USART_IsActiveFlag_REACK(USART3))))
  {
  }

}

static void MX_DMA_Init(void)
{

  /* Init with LL driver */
  /* DMA controller clock enable */
  LL_AHB1_GRP1_EnableClock(LL_AHB1_GRP1_PERIPH_DMAMUX1);
  LL_AHB1_GRP1_EnableClock(LL_AHB1_GRP1_PERIPH_DMA1);
  LL_AHB1_GRP1_EnableClock(LL_AHB1_GRP1_PERIPH_DMA2);

  /* DMA interrupt init */
  /* DMA1_Channel1_IRQn interrupt configuration */
  NVIC_SetPriority(DMA1_Channel1_IRQn, NVIC_EncodePriority(NVIC_GetPriorityGrouping(),0, 0));
  NVIC_EnableIRQ(DMA1_Channel1_IRQn);
  /* DMA1_Channel2_IRQn interrupt configuration */
  NVIC_SetPriority(DMA1_Channel2_IRQn, NVIC_EncodePriority(NVIC_GetPriorityGrouping(),0, 0));
  NVIC_EnableIRQ(DMA1_Channel2_IRQn);
  /* DMA2_Channel1_IRQn interrupt configuration */
  NVIC_SetPriority(DMA2_Channel1_IRQn, NVIC_EncodePriority(NVIC_GetPriorityGrouping(),0, 0));
  NVIC_EnableIRQ(DMA2_Channel1_IRQn);
  /* DMA2_Channel2_IRQn interrupt configuration */
  NVIC_SetPriority(DMA2_Channel2_IRQn, NVIC_EncodePriority(NVIC_GetPriorityGrouping(),0, 0));
  NVIC_EnableIRQ(DMA2_Channel2_IRQn);

}

static void MX_GPIO_Init(void)
{
  LL_EXTI_InitTypeDef EXTI_InitStruct = {0};
  LL_GPIO_InitTypeDef GPIO_InitStruct = {0};

  /* GPIO Ports Clock Enable */
  LL_AHB2_GRP1_EnableClock(LL_AHB2_GRP1_PERIPH_GPIOC);
  LL_AHB2_GRP1_EnableClock(LL_AHB2_GRP1_PERIPH_GPIOF);
  LL_AHB2_GRP1_EnableClock(LL_AHB2_GRP1_PERIPH_GPIOA);
  LL_AHB2_GRP1_EnableClock(LL_AHB2_GRP1_PERIPH_GPIOB);
  LL_AHB2_GRP1_EnableClock(LL_AHB2_GRP1_PERIPH_GPIOD);

  /**/
  LL_GPIO_ResetOutputPin(GPIO_LED_GREEN_GPIO_Port, GPIO_LED_GREEN_Pin);

  /**/
  LL_GPIO_ResetOutputPin(GPIO_LED_RED_GPIO_Port, GPIO_LED_RED_Pin);

  /**/
  LL_GPIO_ResetOutputPin(GPIOA, LL_GPIO_PIN_5);

  /**/
  GPIO_InitStruct.Pin = GPIO_LED_GREEN_Pin;
  GPIO_InitStruct.Mode = LL_GPIO_MODE_OUTPUT;
  GPIO_InitStruct.Speed = LL_GPIO_SPEED_FREQ_LOW;
  GPIO_InitStruct.OutputType = LL_GPIO_OUTPUT_PUSHPULL;
  GPIO_InitStruct.Pull = LL_GPIO_PULL_NO;
  LL_GPIO_Init(GPIO_LED_GREEN_GPIO_Port, &GPIO_InitStruct);

  /**/
  GPIO_InitStruct.Pin = GPIO_LED_RED_Pin;
  GPIO_InitStruct.Mode = LL_GPIO_MODE_OUTPUT;
  GPIO_InitStruct.Speed = LL_GPIO_SPEED_FREQ_LOW;
  GPIO_InitStruct.OutputType = LL_GPIO_OUTPUT_PUSHPULL;
  GPIO_InitStruct.Pull = LL_GPIO_PULL_NO;
  LL_GPIO_Init(GPIO_LED_RED_GPIO_Port, &GPIO_InitStruct);

  /**/
  GPIO_InitStruct.Pin = LL_GPIO_PIN_5;
  GPIO_InitStruct.Mode = LL_GPIO_MODE_OUTPUT;
  GPIO_InitStruct.Speed = LL_GPIO_SPEED_FREQ_LOW;
  GPIO_InitStruct.OutputType = LL_GPIO_OUTPUT_PUSHPULL;
  GPIO_InitStruct.Pull = LL_GPIO_PULL_NO;
  LL_GPIO_Init(GPIOA, &GPIO_InitStruct);

  /**/
  GPIO_InitStruct.Pin = GPIO_MC_SS_Pin;
  GPIO_InitStruct.Mode = LL_GPIO_MODE_INPUT;
  GPIO_InitStruct.Pull = LL_GPIO_PULL_NO;
  LL_GPIO_Init(GPIO_MC_SS_GPIO_Port, &GPIO_InitStruct);

  /**/
  LL_SYSCFG_SetEXTISource(LL_SYSCFG_EXTI_PORTD, LL_SYSCFG_EXTI_LINE2);

  /**/
  EXTI_InitStruct.Line_0_31 = LL_EXTI_LINE_2;
  EXTI_InitStruct.LineCommand = ENABLE;
  EXTI_InitStruct.Mode = LL_EXTI_MODE_IT;
  EXTI_InitStruct.Trigger = LL_EXTI_TRIGGER_RISING;
  LL_EXTI_Init(&EXTI_InitStruct);

  /**/
  LL_GPIO_SetPinPull(TIM3_Zindex_GPIO_Port, TIM3_Zindex_Pin, LL_GPIO_PULL_DOWN);

  /**/
  LL_GPIO_SetPinMode(TIM3_Zindex_GPIO_Port, TIM3_Zindex_Pin, LL_GPIO_MODE_INPUT);

  /* EXTI interrupt init*/
  NVIC_SetPriority(EXTI2_IRQn, NVIC_EncodePriority(NVIC_GetPriorityGrouping(),4, 0));
  NVIC_EnableIRQ(EXTI2_IRQn);

}

void Error_Handler(void)
{
  __disable_irq();
  while (1)
  {
  }
}
